VERSION ""

NS_ :

BS_:

BU_: XXX

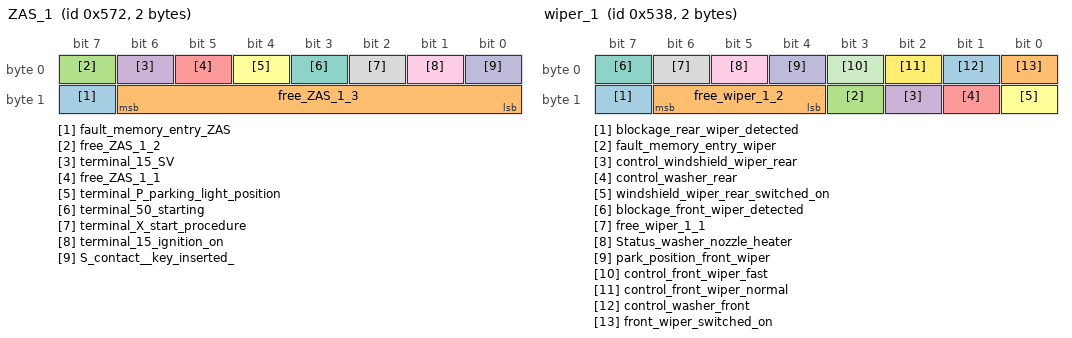
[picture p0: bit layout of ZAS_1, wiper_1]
BO_ 1394 ZAS_1: 2 XXX
 SG_ fault_memory_entry_ZAS : 15|1@1+ (1,0) [0|0] "" XXX
 SG_ free_ZAS_1_3 : 8|7@1+ (1,0) [0|0] "" XXX
 SG_ free_ZAS_1_2 : 7|1@1+ (1,0) [0|0] "" XXX
 SG_ terminal_15_SV : 6|1@1+ (1,0) [0|0] "" XXX
 SG_ free_ZAS_1_1 : 5|1@1+ (1,0) [0|0] "" XXX
 SG_ terminal_P_parking_light_position : 4|1@1+ (1,0) [0|0] "" XXX
 SG_ terminal_50_starting : 3|1@1+ (1,0) [0|0] "" XXX
 SG_ terminal_X_start_procedure : 2|1@1+ (1,0) [0|0] "" XXX
 SG_ terminal_15_ignition_on : 1|1@1+ (1,0) [0|0] "" XXX
 SG_ S_contact__key_inserted_ : 0|1@1+ (1,0) [0|0] "" XXX

BO_ 1336 wiper_1: 2 XXX
 SG_ blockage_rear_wiper_detected : 15|1@1+ (1,0) [0|0] "" XXX
 SG_ free_wiper_1_2 : 12|3@1+ (1,0) [0|0] "" XXX
 SG_ fault_memory_entry_wiper : 11|1@1+ (1,0) [0|0] "" XXX
 SG_ control_windshield_wiper_rear : 10|1@1+ (1,0) [0|0] "" XXX
 SG_ control_washer_rear : 9|1@1+ (1,0) [0|0] "" XXX
 SG_ windshield_wiper_rear_switched_on : 8|1@1+ (1,0) [0|0] "" XXX
 SG_ blockage_front_wiper_detected : 7|1@1+ (1,0) [0|0] "" XXX
 SG_ free_wiper_1_1 : 6|1@1+ (1,0) [0|0] "" XXX
 SG_ Status_washer_nozzle_heater : 5|1@1+ (1,0) [0|0] "" XXX
 SG_ park_position_front_wiper : 4|1@1+ (1,0) [0|0] "" XXX
 SG_ control_front_wiper_fast : 3|1@1+ (1,0) [0|0] "" XXX
 SG_ control_front_wiper_normal : 2|1@1+ (1,0) [0|0] "" XXX
 SG_ control_washer_front : 1|1@1+ (1,0) [0|0] "" XXX
 SG_ front_wiper_switched_on : 0|1@1+ (1,0) [0|0] "" XXX

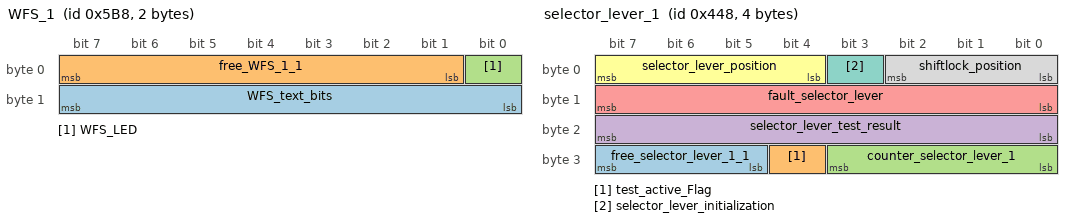
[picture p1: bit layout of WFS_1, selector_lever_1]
BO_ 1464 WFS_1: 2 XXX
 SG_ WFS_text_bits : 8|8@1+ (1,0) [0|0] "" XXX
 SG_ free_WFS_1_1 : 1|7@1+ (1,0) [0|0] "" XXX
 SG_ WFS_LED : 0|1@1+ (1,0) [0|0] "" XXX

BO_ 1096 selector_lever_1: 4 XXX
 SG_ free_selector_lever_1_1 : 29|3@1+ (1,0) [0|0] "" XXX
 SG_ test_active_Flag : 28|1@1+ (1,0) [0|0] "" XXX
 SG_ counter_selector_lever_1 : 24|4@1+ (1,0) [0|15] "" XXX
 SG_ selector_lever_test_result : 16|8@1+ (1,0) [0|255] "" XXX
 SG_ fault_selector_lever : 8|8@1+ (1,0) [0|0] "" XXX
 SG_ selector_lever_position : 4|4@1+ (1,0) [0|0] "" XXX
 SG_ selector_lever_initialization : 3|1@1+ (1,0) [0|0] "" XXX
 SG_ shiftlock_position : 0|3@1+ (1,0) [0|0] "" XXX

BO_ 1496 installation_list_1: 8 XXX
 SG_ TV_tuner : 63|1@1+ (1,0) [0|0] "" XXX
 SG_ DSP : 62|1@1+ (1,0) [0|0] "" XXX
 SG_ CD_changer : 61|1@1+ (1,0) [0|0] "" XXX
 SG_ voice_input : 60|1@1+ (1,0) [0|0] "" XXX
 SG_ telematics : 59|1@1+ (1,0) [0|0] "" XXX
 SG_ Navigation : 58|1@1+ (1,0) [0|0] "" XXX
 SG_ telephone : 57|1@1+ (1,0) [0|0] "" XXX
 SG_ Radio : 56|1@1+ (1,0) [0|0] "" XXX
 SG_ MMI_front : 55|1@1+ (1,0) [0|0] "" XXX
 SG_ MMI_rear : 54|1@1+ (1,0) [0|0] "" XXX
 SG_ free_installation_list_1_11 : 53|1@1+ (1,0) [0|0] "" XXX
 SG_ climate_control_panel_HL : 52|1@1+ (1,0) [0|0] "" XXX
 SG_ free_installation_list_1_10 : 50|2@1+ (1,0) [0|0] "" XXX
 SG_ fuel_level_sender : 49|1@1+ (1,0) [0|0] "" XXX
 SG_ assist_driving_light : 48|1@1+ (1,0) [0|0] "" XXX
 SG_ Memory_behind_driver : 47|1@1+ (1,0) [0|0] "" XXX
 SG_ seat_memory_rear : 46|1@1+ (1,0) [0|0] "" XXX
 SG_ seat_memory_passenger : 45|1@1+ (1,0) [0|0] "" XXX
 SG_ trailer_control_unit : 44|1@1+ (1,0) [0|0] "" XXX
 SG_ energy_management : 43|1@1+ (1,0) [0|0] "" XXX
 SG_ wiper_module : 42|1@1+ (1,0) [0|0] "" XXX
 SG_ EZS___Kessy__comfort_ : 41|1@1+ (1,0) [0|0] "" XXX
 SG_ convertible_top_control_unit : 40|1@1+ (1,0) [0|0] "" XXX
 SG_ auxiliary_heater : 39|1@1+ (1,0) [0|0] "" XXX
 SG_ free_installation_list_1_9 : 38|1@1+ (1,0) [0|0] "" XXX
 SG_ park_assist : 37|1@1+ (1,0) [0|0] "" XXX
 SG_ climate_control_unit_comfort : 36|1@1+ (1,0) [0|0] "" XXX
 SG_ Gateway : 35|1@1+ (1,0) [0|0] "" XXX
 SG_ steering_column_module : 34|1@1+ (1,0) [0|0] "" XXX
 SG_ tire_pressure : 33|1@1+ (1,0) [0|0] "" XXX
 SG_ instrument_cluster_comfort : 32|1@1+ (1,0) [0|0] "" XXX
 SG_ roof_module : 31|1@1+ (1,0) [0|0] "" XXX
 SG_ Memory : 30|1@1+ (1,0) [0|0] "" XXX
 SG_ TSG_HR : 29|1@1+ (1,0) [0|0] "" XXX
 SG_ TSG_HL : 28|1@1+ (1,0) [0|0] "" XXX
 SG_ TSG_BT : 27|1@1+ (1,0) [0|0] "" XXX
 SG_ TSG_FT : 26|1@1+ (1,0) [0|0] "" XXX
 SG_ ZKE : 25|1@1+ (1,0) [0|0] "" XXX
 SG_ BSG_comfort : 24|1@1+ (1,0) [0|0] "" XXX
 SG_ free_installation_list_1_8 : 19|5@1+ (1,0) [0|0] "" XXX
 SG_ Stabi_decoupling : 18|1@1+ (1,0) [0|0] "" XXX
 SG_ selector_lever : 17|1@1+ (1,0) [0|0] "" XXX
 SG_ battery_manager : 16|1@1+ (1,0) [0|0] "" XXX
 SG_ damper_SG : 15|1@1+ (1,0) [0|0] "" XXX
 SG_ level_control : 14|1@1+ (1,0) [0|0] "" XXX
 SG_ EZS___Kessy__drive_ : 13|1@1+ (1,0) [0|0] "" XXX
 SG_ brake_booster : 12|1@1+ (1,0) [0|0] "" XXX
 SG_ steering_assist : 11|1@1+ (1,0) [0|0] "" XXX
 SG_ instrument_cluster_drive : 10|1@1+ (1,0) [0|0] "" XXX
 SG_ injection_pump : 9|1@1+ (1,0) [0|0] "" XXX
 SG_ steering_angle : 8|1@1+ (1,0) [0|0] "" XXX
 SG_ all_wheel_drive : 7|1@1+ (1,0) [0|0] "" XXX
 SG_ BSG_drive : 6|1@1+ (1,0) [0|0] "" XXX
 SG_ ADR : 5|1@1+ (1,0) [0|0] "" XXX
 SG_ airbag : 4|1@1+ (1,0) [0|0] "" XXX
 SG_ Climatronic_drive : 3|1@1+ (1,0) [0|0] "" XXX
 SG_ ABS : 2|1@1+ (1,0) [0|0] "" XXX
 SG_ transmission_control_unit : 1|1@1+ (1,0) [0|0] "" XXX
 SG_ engine_control_unit : 0|1@1+ (1,0) [0|0] "" XXX

BO_ 1488 system_info_1: 6 XXX
 SG_ CAN_state_4_1_powertrain_data_main : 44|4@1+ (1,0) [0|15] "" XXX
 SG_ CAN_state_4_1_powertrain_data_secondary : 40|4@1+ (1,0) [0|15] "" XXX
 SG_ CAN_state_4_1_comfort_data_main : 36|4@1+ (1,0) [0|15] "" XXX
 SG_ CAN_state_4_1_comfort_data_secondary : 32|4@1+ (1,0) [0|15] "" XXX
 SG_ free_system_info_1_6 : 30|1@1+ (1,0) [0|0] "" XXX
 SG_ four_door : 29|1@1+ (1,0) [0|0] "" XXX
 SG_ right_hand_drive : 28|1@1+ (1,0) [0|0] "" XXX
 SG_ vehicle_index : 24|4@1+ (1,0) [0|0] "" XXX
 SG_ vehicle_generation : 20|4@1+ (1,0) [0|15] "" XXX
 SG_ vehicle_derivative : 16|4@1+ (1,0) [0|15] "" XXX
 SG_ vehicle_brand_2 : 12|4@1+ (1,0) [0|15] "" XXX
 SG_ vehicle_class : 8|4@1+ (1,0) [0|15] "" XXX
 SG_ installation_info_valid : 7|1@1+ (1,0) [0|0] "" XXX
 SG_ CAN_Infotainment_installed : 6|1@1+ (1,0) [0|0] "" XXX
 SG_ CAN_Infotainment_in_diagnosis : 5|1@1+ (1,0) [0|0] "" XXX
 SG_ Sleep_CAN_infotainment : 4|1@1+ (1,0) [0|0] "" XXX
 SG_ CAN_comfort_in_diagnosis : 3|1@1+ (1,0) [0|0] "" XXX
 SG_ Sleep_CAN_comfort : 2|1@1+ (1,0) [0|0] "" XXX
 SG_ CAN_powertrain_in_diagnosis : 1|1@1+ (1,0) [0|0] "" XXX
 SG_ CAN_external_connected : 0|1@1+ (1,0) [0|0] "" XXX

BO_ 268 Slave_1: 8 XXX
 SG_ Delta_reduced_desired_torque : 48|1@1+ (1,0) [0|0] "" XXX
 SG_ Delta_throttle_valve_angle : 32|16@1+ (1,0) [0|0] "" XXX
 SG_ free_Slave_1_1 : 25|7@1+ (1,0) [0|0] "" XXX
 SG_ Delta_ignition_angle_output : 24|1@1+ (1,0) [0|0] "" XXX
 SG_ Ubat_enable_DVE_Slave : 23|1@1+ (1,0) [0|0] "" XXX
 SG_ throttle_valve_setpoint_limitation : 22|1@1+ (1,0) [0|0] "" XXX
 SG_ injection_inhibit_learn_Slave : 21|1@1+ (1,0) [0|0] "" XXX
 SG_ Master_detected_Slave : 20|1@1+ (1,0) [0|0] "" XXX
 SG_ fault_torque_output : 19|1@1+ (1,0) [0|0] "" XXX
 SG_ fault_transmission_torque : 18|1@1+ (1,0) [0|0] "" XXX
 SG_ fault_brake_message : 17|1@1+ (1,0) [0|0] "" XXX
 SG_ indicated_actual_torque_Slave : 0|16@1+ (0.0015259,0) [0|99.998] "%" XXX
 SG_ Timeout_brake_message : 0|1@1+ (1,0) [0|0] "" XXX

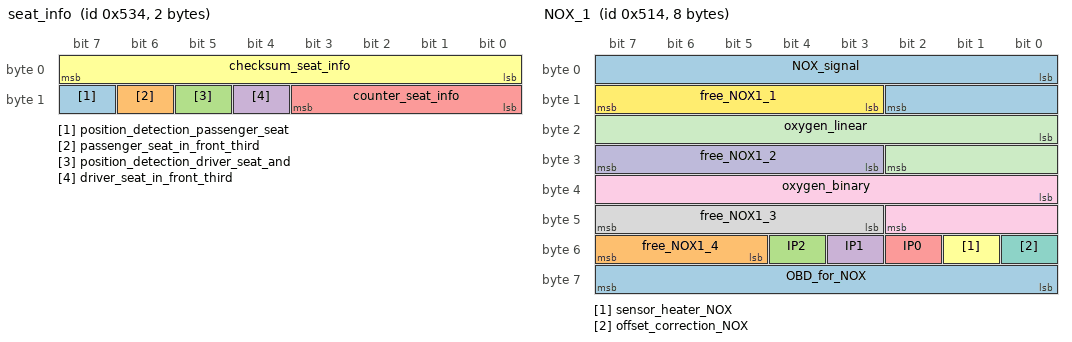
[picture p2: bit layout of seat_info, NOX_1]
BO_ 1332 seat_info: 2 XXX
 SG_ position_detection_passenger_seat : 15|1@1+ (1,0) [0|0] "" XXX
 SG_ passenger_seat_in_front_third : 14|1@1+ (1,0) [0|0] "" XXX
 SG_ position_detection_driver_seat_and : 13|1@1+ (1,0) [0|0] "" XXX
 SG_ driver_seat_in_front_third : 12|1@1+ (1,0) [0|0] "" XXX
 SG_ counter_seat_info : 8|4@1+ (1,0) [0|15] "" XXX
 SG_ checksum_seat_info : 0|8@1+ (1,0) [0|0] "" XXX

BO_ 1810 PSG_3: 2 XXX
 SG_ self_test_result : 0|16@1+ (1,0) [0|0] "" XXX

BO_ 1298 PSG_2: 8 XXX
 SG_ RAM_content_4 : 48|16@1+ (1,0) [0|0] "" XXX
 SG_ RAM_content_3 : 32|16@1+ (1,0) [0|0] "" XXX
 SG_ RAM_content_2 : 16|16@1+ (1,0) [0|0] "" XXX
 SG_ RAM_content_1 : 0|16@1+ (1,0) [0|0] "" XXX

BO_ 274 PSG_1: 8 XXX
 SG_ pump_temperature__2_1_ : 48|16@1+ (0.0625,0) [0|4096] "K" XXX
 SG_ pump_temperature__3_2_2_ : 44|12@1+ (1,0) [0|0] "" XXX
 SG_ cylinder_counter__3_2_2_ : 43|3@1+ (1,0) [1|8] "counter" XXX
 SG_ control_duration__3_2_2_ : 32|11@1+ (0.0469,0) [0|96] "NW" XXX
 SG_ camshaft_rpm__3_2_2_ : 20|12@1+ (4,0) [0|16380] "upm" XXX
 SG_ pump_status_word__3_2_2_ : 0|20@1+ (1,0) [0|0] "" XXX

BO_ 1300 NOX_1: 8 XXX
 SG_ OBD_for_NOX : 56|8@1+ (1,0) [0|0] "" XXX
 SG_ free_NOX1_4 : 53|3@1+ (1,0) [0|0] "" XXX
 SG_ IP2 : 52|1@1+ (1,0) [0|0] "" XXX
 SG_ IP1 : 51|1@1+ (1,0) [0|0] "" XXX
 SG_ IP0 : 50|1@1+ (1,0) [0|0] "" XXX
 SG_ sensor_heater_NOX : 49|1@1+ (1,0) [0|0] "" XXX
 SG_ offset_correction_NOX : 48|1@1+ (1,0) [0|0] "" XXX
 SG_ free_NOX1_3 : 43|5@1+ (1,0) [0|0] "" XXX
 SG_ oxygen_binary : 32|11@1+ (1,-200) [-200|1847] "mV" XXX
 SG_ free_NOX1_2 : 27|5@1+ (1,0) [0|0] "" XXX
 SG_ oxygen_linear : 16|11@1+ (1,0) [0|2047] "1000/Lambd" XXX
 SG_ free_NOX1_1 : 11|5@1+ (1,0) [0|0] "" XXX
 SG_ NOX_signal : 0|11@1+ (1,0) [0|2047] "ppm" XXX

BO_ 1424 level_1: 6 XXX
 SG_ load_state : 40|8@1+ (1,0) [0|253] "Zuladung" XXX
 SG_ fault_memory_entry_level_1 : 39|1@1+ (1,0) [0|0] "" XXX
 SG_ system_status_level_1 : 38|1@1+ (1,0) [0|0] "" XXX
 SG_ reserve_vehicle_type : 37|1@1+ (1,0) [0|0] "" XXX
 SG_ vehicle_type_level : 36|1@1+ (1,0) [0|0] "" XXX
 SG_ text_bits_level_1 : 32|4@1+ (1,0) [0|0] "" XXX
 SG_ adjustment_HL : 31|1@1+ (1,0) [0|0] "" XXX
 SG_ adjustment_HR : 30|1@1+ (1,0) [0|0] "" XXX
 SG_ adjustment_VL : 29|1@1+ (1,0) [0|0] "" XXX
 SG_ adjustment_VR : 28|1@1+ (1,0) [0|0] "" XXX
 SG_ lowering_vehicle : 27|1@1+ (1,0) [0|0] "" XXX
 SG_ raise_vehicle : 26|1@1+ (1,0) [0|0] "" XXX
 SG_ adjustment_active : 25|1@1+ (1,0) [0|0] "" XXX
 SG_ compressor_run_shortly : 24|1@1+ (1,0) [0|0] "" XXX
 SG_ free_level_1_5 : 23|1@1+ (1,0) [0|0] "" XXX
 SG_ button_level : 22|1@1+ (1,0) [0|0] "" XXX
 SG_ park_level : 21|1@1+ (1,0) [0|0] "" XXX
 SG_ intermediate_level : 20|1@1+ (1,0) [0|0] "" XXX
 SG_ level_status : 16|4@1+ (1,0) [0|0] "" XXX
 SG_ MSG_limitation : 15|1@1+ (1,0) [0|0] "" XXX
 SG_ ESP_influence : 14|1@1+ (1,0) [0|0] "" XXX
 SG_ warning_lamp_level_1 : 13|1@1+ (1,0) [0|0] "" XXX
 SG_ free_level_1_1 : 12|1@1+ (1,0) [0|0] "" XXX
 SG_ counter_level_1 : 8|4@1+ (1,0) [0|15] "counter" XXX
 SG_ checksum_level_1 : 0|8@1+ (1,0) [0|0] "" XXX

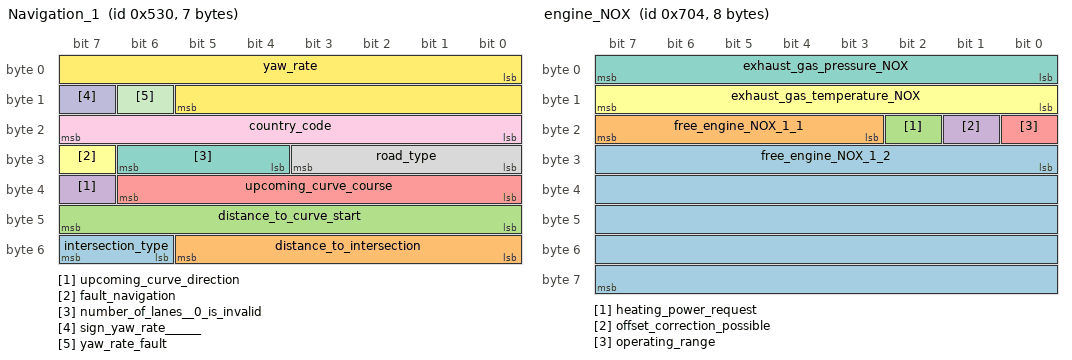
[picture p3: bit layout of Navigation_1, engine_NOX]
BO_ 1328 Navigation_1: 7 XXX
 SG_ intersection_type : 54|2@1+ (1,0) [0|3] "" XXX
 SG_ distance_to_intersection : 48|6@1+ (5,0) [0|315] "m" XXX
 SG_ distance_to_curve_start : 40|8@1+ (1,0) [0|255] "m" XXX
 SG_ upcoming_curve_direction : 39|1@1+ (1,0) [0|0] "" XXX
 SG_ upcoming_curve_course : 32|7@1+ (50,0) [0|6350] "m" XXX
 SG_ fault_navigation : 31|1@1+ (1,0) [0|0] "" XXX
 SG_ number_of_lanes__0_is_invalid : 28|3@1+ (1,0) [1|7] "" XXX
 SG_ road_type : 24|4@1+ (1,0) [0|15] "" XXX
 SG_ country_code : 16|8@1+ (1,0) [0|0] "" XXX
 SG_ sign_yaw_rate______ : 15|1@1+ (1,0) [0|0] "" XXX
 SG_ yaw_rate_fault : 14|1@1+ (1,0) [0|0] "" XXX
 SG_ yaw_rate : 0|14@1+ (0.01,0) [0|100] "deg/sek" XXX

BO_ 1792 MSG_3: 3 XXX
 SG_ MSG_configuration : 16|8@1+ (1,0) [0|0] "" XXX
 SG_ position_of_OT_pulse : 0|16@1+ (0.01172,-384) [-384|384] "KW" XXX

BO_ 1280 MSG_2: 8 XXX
 SG_ RAM_address_4 : 48|16@1+ (1,0) [0|0] "" XXX
 SG_ RAM_address_3 : 32|16@1+ (1,0) [0|0] "" XXX
 SG_ RAM_address_2 : 16|16@1+ (1,0) [0|0] "" XXX
 SG_ RAM_address_1 : 0|16@1+ (1,0) [0|0] "" XXX

BO_ 256 MSG_1: 8 XXX
 SG_ crankshaft_rpm_3_2_2 : 56|8@1+ (1,0) [0|0] "" XXX
 SG_ desired_delivery_start_KW__3_2_2_ : 40|16@1+ (0.01172,-384) [-384|384] "KW" XXX
 SG_ desired_delivery_start_NW__3_2_2_ : 28|12@1+ (0.01172,0) [0|768] "degNW" XXX
 SG_ desired_pre_injection : 16|12@1+ (1,0) [0|0] "" XXX
 SG_ desired_injection_quantity : 0|16@1+ (0.03125,0) [0|2047] "mg/H" XXX

BO_ 1796 engine_NOX: 8 XXX
 SG_ free_engine_NOX_1_2 : 24|40@1+ (1,0) [0|0] "" XXX
 SG_ free_engine_NOX_1_1 : 19|5@1+ (1,0) [0|0] "" XXX
 SG_ heating_power_request : 18|1@1+ (1,0) [0|0] "" XXX
 SG_ offset_correction_possible : 17|1@1+ (1,0) [0|0] "" XXX
 SG_ operating_range : 16|1@1+ (1,0) [0|0] "" XXX
 SG_ exhaust_gas_temperature_NOX : 8|8@1+ (5,-40) [-40|1230] "C" XXX
 SG_ exhaust_gas_pressure_NOX : 0|8@1+ (5,600) [600|1870] "mbar" XXX

BO_ 900 engine_torques: 8 XXX
 SG_ torque_values_inaccurate_torque : 35|2@1+ (1,0) [0|0] "" XXX

BO_ 1408 engine_Flexia: 8 XXX
 SG_ intake_system m0 : 63|1@1+ (1,0) [0|0] "" XXX
 SG_ displacement m0 : 56|7@1+ (0.1,0) [0|12.7] "l" XXX
 SG_ slope_of_the_filling_characteristic_curve m1 : 56|8@1+ (0.001,0) [0|0.255] "l/mm" XXX
 SG_ number_of_cylinders m0 : 52|4@1+ (1,0) [0|15] "Vent./Zyl." XXX
 SG_ rating_factor_soot_index_Turb m1 : 50|6@1+ (0.1,0) [0|6.3] "" XXX
 SG_ number_of_valves m0 : 49|3@1+ (1,0) [0|7] "Vent./Zyl." XXX
 SG_ rating_factor_wear_index m1 : 44|6@1+ (0.1,0) [0|6.3] "" XXX
 SG_ manufacturer_Code m1 : 40|4@1+ (1,0) [0|15] "" XXX
 SG_ engine_power m0 : 40|9@1+ (1,0) [0|512] "KW" XXX
 SG_ Max_torque m0 : 32|8@1+ (10,0) [0|2550] "Nm" XXX
 SG_ normalized_consumption m1 : 32|8@1+ (10,0) [0|2550] "l/Zyl." XXX
 SG_ oil_level_threshold m1 : 24|8@1+ (0.25,0) [0|63.75] "cm" XXX
 SG_ rpm_MaxNorm m0 : 24|8@1+ (100,0) [0|25500] "U/min" XXX
 SG_ wear_index : 16|8@1+ (1,0) [0|254] "" XXX
 SG_ soot_index : 8|8@1+ (1,0) [0|254] "" XXX
 SG_ combustion_type : 7|1@1+ (1,0) [0|0] "" XXX
 SG_ free_engine_Flexia_1 : 6|1@1+ (1,0) [0|0] "" XXX
 SG_ Warm_Up_Cycle : 5|1@1+ (1,0) [0|0] "" XXX
 SG_ Driving_Cycle : 4|1@1+ (1,0) [0|0] "" XXX
 SG_ counter_engine_Flexia : 1|3@1+ (1,0) [0|15] "" XXX
 SG_ multiplex_switch_engine_Flexia M : 0|1@1+ (1,0) [0|0] "" XXX

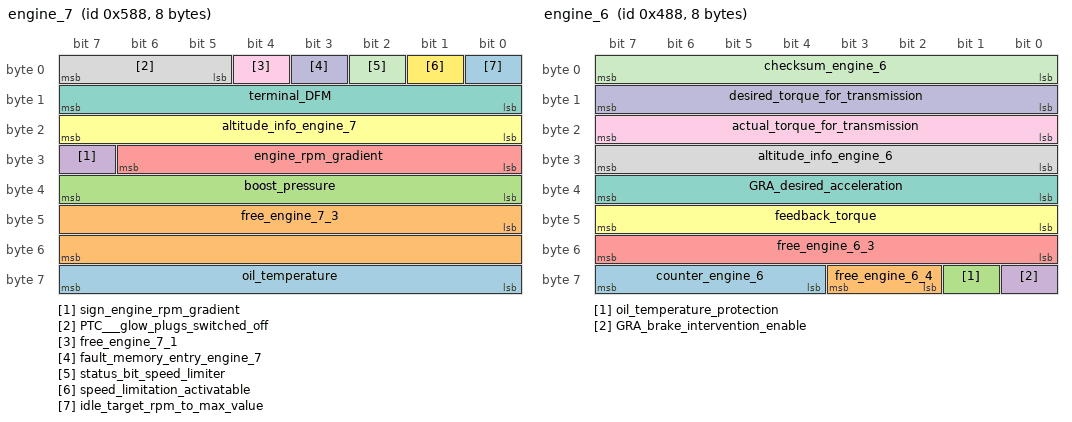
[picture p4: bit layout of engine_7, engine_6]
BO_ 1416 engine_7: 8 XXX
 SG_ oil_temperature : 56|8@1+ (1,0) [0|0] "" XXX
 SG_ free_engine_7_3 : 40|16@1+ (1,0) [0|0] "" XXX
 SG_ boost_pressure : 32|8@1+ (0.01,0) [0|2.54] "bar" XXX
 SG_ sign_engine_rpm_gradient : 31|1@1+ (1,0) [0|0] "" XXX
 SG_ engine_rpm_gradient : 24|7@1+ (1,0) [0|126] "U/min" XXX
 SG_ altitude_info_engine_7 : 16|8@1+ (0.00787,0) [0|2] "" XXX
 SG_ terminal_DFM : 8|8@1+ (0.4,0) [0|101.6] "%" XXX
 SG_ PTC___glow_plugs_switched_off : 5|3@1+ (1,0) [0|0] "" XXX
 SG_ free_engine_7_1 : 4|1@1+ (1,0) [0|0] "" XXX
 SG_ fault_memory_entry_engine_7 : 3|1@1+ (1,0) [0|0] "" XXX
 SG_ status_bit_speed_limiter : 2|1@1+ (1,0) [0|0] "" XXX
 SG_ speed_limitation_activatable : 1|1@1+ (1,0) [0|0] "" XXX
 SG_ idle_target_rpm_to_max_value : 0|1@1+ (1,0) [0|0] "" XXX

BO_ 1160 engine_6: 8 XXX
 SG_ counter_engine_6 : 60|4@1+ (1,0) [0|15] "" XXX
 SG_ free_engine_6_4 : 58|2@1+ (1,0) [0|0] "" XXX
 SG_ oil_temperature_protection : 57|1@1+ (1,0) [0|0] "" XXX
 SG_ GRA_brake_intervention_enable : 56|1@1+ (1,0) [0|0] "" XXX
 SG_ free_engine_6_3 : 48|8@1+ (1,0) [0|0] "" XXX
 SG_ feedback_torque : 40|8@1+ (0.39,0) [0|100] "" XXX
 SG_ GRA_desired_acceleration : 32|8@1+ (0.024,-3.984) [-3.984|2.112] "m/s2" XXX
 SG_ altitude_info_engine_6 : 24|8@1+ (0.00787,0) [0|2] "" XXX
 SG_ actual_torque_for_transmission : 16|8@1+ (0.39,0) [0|99] "MDI" XXX
 SG_ desired_torque_for_transmission : 8|8@1+ (0.39,0) [0|99] "MDI" XXX
 SG_ checksum_engine_6 : 0|8@1+ (1,0) [0|0] "" XXX

BO_ 1152 engine_5: 8 engine
 SG_ MO5_Mp_Code M : 6|2@1+ (1,0) [0|3] "" Gateway
 SG_ MO5_max_torque m0 : 0|6@1+ (10,0) [0|630] "Nm" Gateway
 SG_ MO5_engine_speed m1 : 0|6@1+ (100,0) [0|6300] "U/min" Gateway
 SG_ MO5_engine_type m2 : 0|6@1+ (1,0) [0|63] "" Gateway
 SG_ MO5_exhaust_type m3 : 0|1@1+ (1,0) [0|1] "" Gateway
 SG_ MO5_exhaust_type2 m3 : 1|1@1+ (1,0) [0|1] "" Gateway
 SG_ MO5_exhaust_type3 m3 : 2|1@1+ (1,0) [0|1] "" Gateway
 SG_ OBD_cold_start_Denominator m3 : 3|1@1+ (1,0) [0|1] "" Gateway
 SG_ OBD_Minimum_Trip m3 : 4|1@1+ (1,0) [0|1] "" Gateway
 SG_ MO5_DPF_reg m3 : 5|1@1+ (1,0) [0|1] "" Gateway
 SG_ MO5_preheat : 9|1@1+ (1,0) [0|1] "" KOMBI
 SG_ MO5_E_throttle : 10|1@1+ (1,0) [0|1] "" KOMBI
 SG_ MO5_OBD_2 : 11|1@1+ (1,0) [0|1] "" KOMBI
 SG_ MO5_hot_run : 12|1@1+ (1,0) [0|1] "" KOMBI
 SG_ MO5_climate_compressor : 13|1@1+ (1,0) [0|1] "" Gateway
 SG_ MO5_field_cooling : 14|1@1+ (1,0) [0|1] "" Gateway
 SG_ MO5_KliKo_Red : 15|1@1+ (1,0) [0|1] "" Gateway
 SG_ MO5_consumption : 16|15@1+ (1,0) [0|32767] "µl" KOMBI
 SG_ MO5_overflow_consumption : 31|1@1+ (1,0) [0|1] "" KOMBI
 SG_ MO5_fan : 32|8@1+ (0.4,0) [0|101.6] "%" Gateway
 SG_ MO5_HLeuchte : 40|1@1+ (1,0) [0|1] "" KOMBI
 SG_ MO5_particle_lamp : 41|1@1+ (1,0) [0|1] "" KOMBI
 SG_ MO5_Sta_BKU : 42|1@1+ (1,0) [0|1] "" Gateway
 SG_ MO5_type_start_control : 43|1@1+ (1,0) [0|1] "" Gateway
 SG_ MO5_TDE_lamp : 44|1@1+ (1,0) [0|1] "" KOMBI
 SG_ MO5_TDE_Text : 45|1@1+ (1,0) [0|1] "" KOMBI
 SG_ MO5_DZM_damping : 46|1@1+ (1,0) [0|1] "" KOMBI
 SG_ MO5_Interlock : 47|1@1+ (1,0) [0|1] "" Gateway
 SG_ MO5_Start : 48|1@1+ (1,0) [0|1] "" Gateway
 SG_ MO5_starter : 49|1@1+ (1,0) [0|1] "" Gateway
 SG_ MO5_GRA_main_switch : 50|1@1+ (1,0) [0|1] "" Gateway
 SG_ MO5_torques : 51|1@1+ (1,0) [0|1] "" Gateway
 SG_ MO5_engine_text1 : 52|1@1+ (1,0) [0|1] "" KOMBI
 SG_ MO5_engine_text2 : 53|1@1+ (1,0) [0|1] "" KOMBI
 SG_ MO5_engine_text3 : 54|1@1+ (1,0) [0|1] "" KOMBI
 SG_ MO5_engine_text4 : 55|1@1+ (1,0) [0|1] "" KOMBI
 SG_ CHECKSUM : 56|8@1+ (1,0) [0|255] "" Gateway

BO_ 896 engine_3: 8 engine
 SG_ MO3_preglow : 0|1@1+ (1,0) [0|1] "" Gateway
 SG_ MO3_Prio_Dz : 1|1@1+ (1,0) [0|1] "" Transmission
 SG_ MO_switch_StartStopp : 2|1@1+ (1,0) [0|1] "" Gateway
 SG_ MO3_winter_program : 3|1@1+ (1,0) [0|1] "" Transmission
 SG_ MO3_Sta_pedal : 4|1@1+ (1,0) [0|1] "" Gateway
 SG_ MO3_Sta_FPG M : 5|1@1+ (1,0) [0|1] "" ESP
 SG_ MO3_Sign_FPG m1 : 6|1@1+ (1,0) [0|1] "" ESP
 SG_ MO3_Sta_temp : 7|1@1+ (1,0) [0|1] "" Gateway
 SG_ MO3_offset_temp : 8|8@1+ (0.75,-48) [-48|142.5] "°C" Gateway
 SG_ MO3_pedal_value : 16|8@1+ (0.4,0) [0|101.6] "%" Gateway
 SG_ MO3_wheel_Wu_torque : 24|12@1+ (0.39,0) [0|1596.66] "%" Transmission
 SG_ MO3_sign_wheelWu : 36|1@1+ (1,0) [0|1] "" Transmission
 SG_ MO3_release_coasting : 37|1@1+ (1,0) [0|1] "" Transmission
 SG_ MO_StartStopp_stop_preparation : 38|1@1+ (1,0) [0|1] "" Gateway
 SG_ MO3_Dz_influence : 40|8@1+ (0.39,0) [0|99.45] "%" Transmission
 SG_ MO3_target_Dz : 48|8@1+ (25,0) [0|6350] "U/min" Transmission
 SG_ MO3_DKW m0 : 56|8@1+ (0.4,0) [0|101.6] "%" Gateway
 SG_ MO3_FPGradient m1 : 56|8@1+ (25,0) [0|6350] "%/s" ESP

BO_ 648 engine_2: 8 engine
 SG_ MO2_Mp_code m : 6|2@1+ (1,0) [0|3] "" Gateway
 SG_ MO2_transmission_code m2 : 0|6@1+ (1,0) [0|63] "" Gateway
 SG_ MO2_max_torque m3 : 0|6@1+ (10,0) [0|630] "Nm" Gateway
 SG_ MO2_CAN_version m0 : 0|6@1+ (1,0) [0|63] "" Gateway
 SG_ MO2_motor_code m1 : 0|6@1+ (1,0) [0|63] "" Gateway
 SG_ MO2_coolant_T : 8|8@1+ (0.75,-48) [-47.25|142.5] "°C" Gateway
 SG_ MO2_BLS : 16|1@1+ (1,0) [0|1] "" Gateway
 SG_ MO2_BTS : 17|1@1+ (1,0) [0|1] "" Gateway
 SG_ MO2_Sta_coolant : 18|1@1+ (1,0) [0|1] "" Gateway
 SG_ MO2_Sta_climate : 19|1@1+ (1,0) [0|1] "" Gateway
 SG_ MO2_Sta_No_operation : 20|1@1+ (1,0) [0|1] "" Gateway
 SG_ MO2_Status_TSK : 21|1@1+ (1,0) [0|1] "" Gateway
 SG_ MO2_Sta_GRA : 22|2@1+ (1,0) [0|3] "" ACC,GRA
 SG_ TSK_limiter_selected : 25|1@1+ (1,0) [0|1] "" ACC,GRA
 SG_ MO2_GRA_controls : 26|1@1+ (1,0) [0|1] "" Gateway
 SG_ MO2_Sport_Error : 27|1@1+ (1,0) [0|1] "" Gateway
 SG_ MO2_OffRoad : 28|1@1+ (1,0) [0|1] "" Gateway
 SG_ MO2_RME_content : 29|3@1+ (12.5,0) [0|75] "%" Gateway
 SG_ MO2_GRA_target : 32|8@1+ (1.28,0) [0|325.12] "km/h" ACC,GRA
 SG_ MO2_LL_target_speed : 40|8@1+ (10,0) [0|2540] "1/min" Gateway
 SG_ MO2_limit_Mo : 48|8@1+ (0.39,0) [0|99.06] "%" Gateway
 SG_ MO2_Mo_ZWR : 56|8@1+ (0.39,0) [0|99.06] "%" Gateway

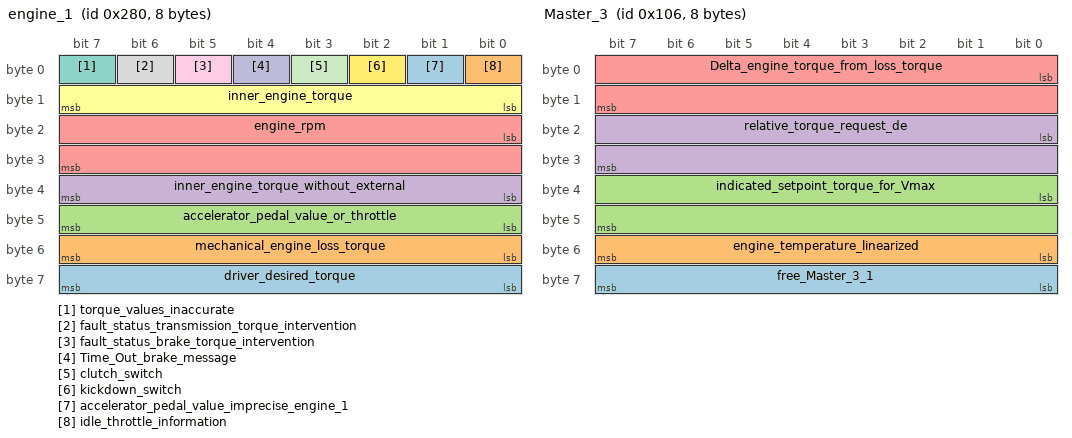
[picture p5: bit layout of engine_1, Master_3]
BO_ 640 engine_1: 8 XXX
 SG_ driver_desired_torque : 56|8@1+ (0.39,0) [0|99] "MDI" XXX
 SG_ mechanical_engine_loss_torque : 48|8@1+ (0.39,0) [0|99] "MDI" XXX
 SG_ accelerator_pedal_value_or_throttle : 40|8@1+ (0.4,0) [0|101.6] "%" XXX
 SG_ inner_engine_torque_without_external : 32|8@1+ (0.39,0) [0|99] "MDI" XXX
 SG_ engine_rpm : 16|16@1+ (0.25,0) [0|16256] "U/min" XXX
 SG_ inner_engine_torque : 8|8@1+ (0.39,0) [0|99] "MDI" XXX
 SG_ torque_values_inaccurate : 7|1@1+ (1,0) [0|0] "" XXX
 SG_ fault_status_transmission_torque_intervention : 6|1@1+ (1,0) [0|0] "" XXX
 SG_ fault_status_brake_torque_intervention : 5|1@1+ (1,0) [0|0] "" XXX
 SG_ Time_Out_brake_message : 4|1@1+ (1,0) [0|0] "" XXX
 SG_ clutch_switch : 3|1@1+ (1,0) [0|0] "" XXX
 SG_ kickdown_switch : 2|1@1+ (1,0) [0|0] "" XXX
 SG_ accelerator_pedal_value_imprecise_engine_1 M : 1|1@1+ (1,0) [0|0] "" XXX
 SG_ idle_throttle_information : 0|1@1+ (1,0) [0|0] "" XXX

BO_ 262 Master_3: 8 XXX
 SG_ free_Master_3_1 : 56|8@1+ (1,0) [0|0] "" XXX
 SG_ engine_temperature_linearized : 48|8@1+ (0.75,-48) [-48|143.25] "" XXX
 SG_ indicated_setpoint_torque_for_Vmax : 32|16@1+ (0.0015259,0) [0|100] "%" XXX
 SG_ relative_torque_request_de : 16|16@1+ (0.003052,0) [0|200] "%" XXX
 SG_ Delta_engine_torque_from_loss_torque : 0|16@1+ (0.003052,-100) [-100|100] "%" XXX

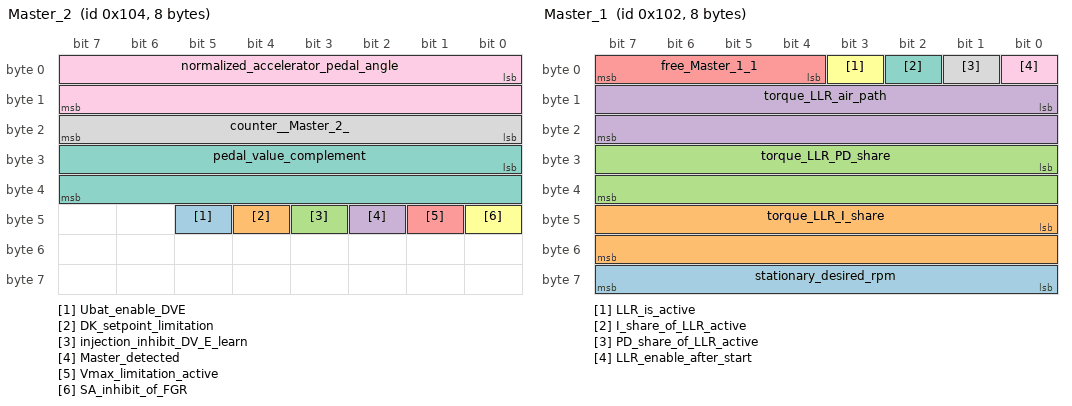
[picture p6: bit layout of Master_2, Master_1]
BO_ 260 Master_2: 8 XXX
 SG_ Ubat_enable_DVE : 45|1@1+ (1,0) [0|0] "" XXX
 SG_ DK_setpoint_limitation : 44|1@1+ (1,0) [0|0] "" XXX
 SG_ injection_inhibit_DV_E_learn : 43|1@1+ (1,0) [0|0] "" XXX
 SG_ Master_detected : 42|1@1+ (1,0) [0|0] "" XXX
 SG_ Vmax_limitation_active : 41|1@1+ (1,0) [0|0] "" XXX
 SG_ SA_inhibit_of_FGR : 40|1@1+ (1,0) [0|0] "" XXX
 SG_ pedal_value_complement : 24|16@1+ (1,0) [0|0] "" XXX
 SG_ counter__Master_2_ : 16|8@1+ (1,0) [0|255] "" XXX
 SG_ normalized_accelerator_pedal_angle : 0|16@1+ (0.001526,0) [0|100] "%" XXX

BO_ 258 Master_1: 8 XXX
 SG_ stationary_desired_rpm : 56|8@1+ (10,0) [0|2550] "Umin" XXX
 SG_ torque_LLR_I_share : 40|16@1+ (0.003052,-100) [-100|100] "%" XXX
 SG_ torque_LLR_PD_share : 24|16@1+ (0.003052,-100) [-100|100] "%" XXX
 SG_ torque_LLR_air_path : 8|16@1+ (0.003052,-100) [-100|100] "%" XXX
 SG_ free_Master_1_1 : 4|4@1+ (1,0) [0|0] "" XXX
 SG_ LLR_is_active : 3|1@1+ (1,0) [0|0] "" XXX
 SG_ I_share_of_LLR_active : 2|1@1+ (1,0) [0|0] "" XXX
 SG_ PD_share_of_LLR_active : 1|1@1+ (1,0) [0|0] "" XXX
 SG_ LLR_enable_after_start : 0|1@1+ (1,0) [0|0] "" XXX

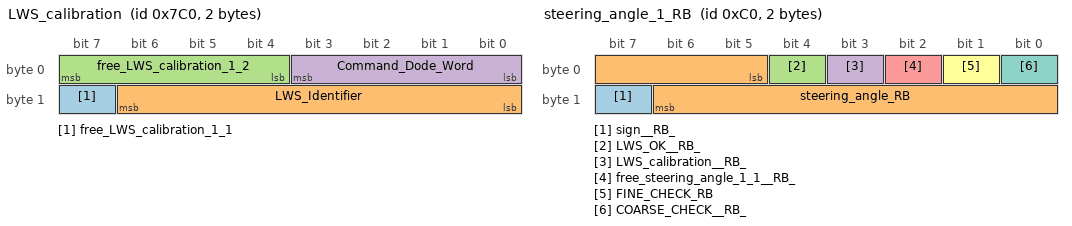
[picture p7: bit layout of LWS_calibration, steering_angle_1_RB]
BO_ 1984 LWS_calibration: 2 XXX
 SG_ free_LWS_calibration_1_1 : 15|1@1+ (1,0) [0|0] "" XXX
 SG_ LWS_Identifier : 8|7@1+ (1,0) [0|0] "" XXX
 SG_ free_LWS_calibration_1_2 : 4|4@1+ (1,0) [0|0] "" XXX
 SG_ Command_Dode_Word : 0|4@1+ (1,0) [0|0] "" XXX

BO_ 1986 steering_angle_Init: 4 XXX
 SG_ coding_bytes : 8|24@1+ (1,0) [0|0] "" XXX
 SG_ identifier_for_LWS_init : 0|8@1+ (1,0) [0|0] "" XXX

BO_ 192 steering_angle_1_RB: 2 XXX
 SG_ sign__RB_ : 15|1@1+ (1,0) [0|0] "" XXX
 SG_ steering_angle_RB : 5|10@1+ (2.5,-720) [-720|720] "" XXX
 SG_ LWS_OK__RB_ : 4|1@1+ (1,0) [0|0] "" XXX
 SG_ LWS_calibration__RB_ : 3|1@1+ (1,0) [0|0] "" XXX
 SG_ free_steering_angle_1_1__RB_ : 2|1@1+ (1,0) [0|0] "" XXX
 SG_ FINE_CHECK_RB : 1|1@1+ (1,0) [0|0] "" XXX
 SG_ COARSE_CHECK__RB_ : 0|1@1+ (1,0) [0|0] "" XXX

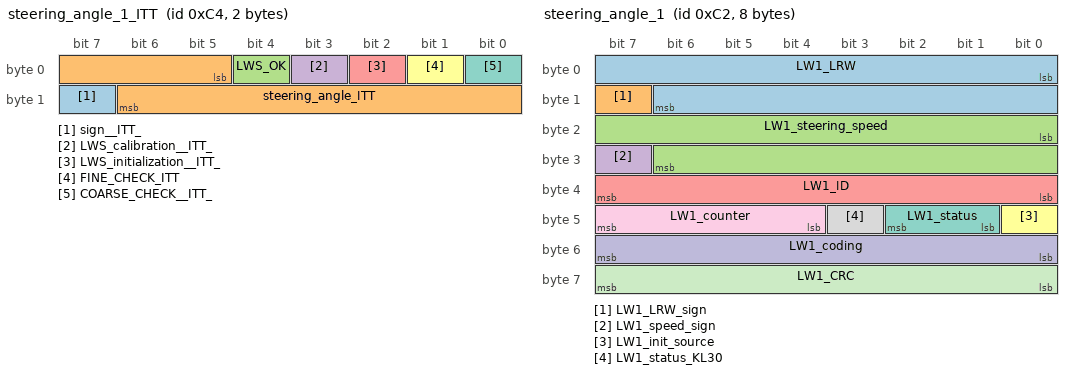
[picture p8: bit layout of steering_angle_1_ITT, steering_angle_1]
BO_ 196 steering_angle_1_ITT: 2 XXX
 SG_ sign__ITT_ : 15|1@1+ (1,0) [0|0] "" XXX
 SG_ steering_angle_ITT : 5|10@1+ (1.5,-768) [-768|766.5] "" XXX
 SG_ LWS_OK : 4|1@1+ (1,0) [0|0] "" XXX
 SG_ LWS_calibration__ITT_ : 3|1@1+ (1,0) [0|0] "" XXX
 SG_ LWS_initialization__ITT_ : 2|1@1+ (1,0) [0|0] "" XXX
 SG_ FINE_CHECK_ITT : 1|1@1+ (1,0) [0|0] "" XXX
 SG_ COARSE_CHECK__ITT_ : 0|1@1+ (1,0) [0|0] "" XXX

BO_ 194 steering_angle_1: 8 XXX
 SG_ LW1_LRW : 0|15@1+ (0.04375,0) [0|1433.55625] "°Grad" Gateway,ESP,ABS
 SG_ LW1_LRW_sign : 15|1@1+ (1,0) [0|1] "" Gateway,ESP,ABS
 SG_ LW1_steering_speed : 16|15@1+ (0.04375,0) [0|1433.55625] "°Grad/s" Gateway,ESP,ABS
 SG_ LW1_speed_sign : 31|1@1+ (1,0) [0|1] "" Gateway,ESP,ABS
 SG_ LW1_ID : 32|8@1+ (1,0) [0|255] "" Gateway,ESP,ABS
 SG_ LW1_init_source : 40|1@1+ (1,0) [0|1] "" Gateway,ESP,ABS
 SG_ LW1_status : 41|2@1+ (1,0) [0|3] "" Gateway,ESP,ABS
 SG_ LW1_status_KL30 : 43|1@1+ (1,0) [0|1] "" Gateway,ESP,ABS
 SG_ LW1_counter : 44|4@1+ (1,0) [0|15] "" Gateway,ESP,ABS
 SG_ LW1_coding : 48|8@1+ (1,0) [0|255] "" Gateway
 SG_ LW1_CRC : 56|8@1+ (1,0) [0|255] "" Gateway,ESP,ABS

BO_ 1502 steering_assist_fault: 7 XXX
 SG_ workshop_code : 48|8@1+ (1,0) [0|0] "" XXX
 SG_ multiplex_signal : 45|3@1+ (1,0) [0|7] "" XXX
 SG_ sensor_coding_steering_assist : 44|1@1+ (1,0) [0|0] "" XXX
 SG_ characteristic_curve_coding_steering_assist : 40|4@1+ (1,0) [0|15] "Kennlinie" XXX
 SG_ sensor_for_steering_angle_memory_read : 39|1@1+ (1,0) [0|0] "" XXX
 SG_ instrument_cluster_read_memory : 38|1@1+ (1,0) [0|0] "" XXX
 SG_ control_unit_read_out_memory : 37|1@1+ (1,0) [0|0] "" XXX
 SG_ steering_assist_ECU_defective : 36|1@1+ (1,0) [0|0] "" XXX
 SG_ free_power_steering_1_3 : 32|4@1+ (1,0) [0|0] "" XXX
 SG_ free_power_steering_1_4 : 30|2@1+ (1,0) [0|0] "" XXX
 SG_ sensor_for_steering_angle_no_CAN_comm : 29|1@1+ (1,0) [0|0] "" XXX
 SG_ sensor_for_steering_angle_no_CAN_comm : 28|1@1+ (1,0) [0|0] "" XXX
 SG_ instrument_cluster_no_CAN_communication_stored : 27|1@1+ (1,0) [0|0] "" XXX
 SG_ instrument_cluster_no_CAN_communication : 26|1@1+ (1,0) [0|0] "" XXX
 SG_ control_unit_no_CAN_communication_S : 25|1@1+ (1,0) [0|0] "" XXX
 SG_ control_unit_no_CAN_communication : 24|1@1+ (1,0) [0|0] "" XXX
 SG_ steering_assist_voltage_Ks_to_ground : 23|1@1+ (1,0) [0|0] "" XXX
 SG_ steering_assist_voltage_Ks_to_ground : 22|1@1+ (1,0) [0|0] "" XXX
 SG_ steering_assist_voltage_Ks_to_ground_stored : 21|1@1+ (1,0) [0|0] "" XXX
 SG_ steering_assist_voltage_Ks_to_ground : 20|1@1+ (1,0) [0|0] "" XXX
 SG_ steering_assist_temperature_protection_stored : 19|1@1+ (1,0) [0|0] "" XXX
 SG_ steering_assist_temperature_protection : 18|1@1+ (1,0) [0|0] "" XXX
 SG_ steering_assist_operation_implausible_signal_stored : 17|1@1+ (1,0) [0|0] "" XXX
 SG_ steering_assist_operation_implausible_signal : 16|1@1+ (1,0) [0|0] "" XXX
 SG_ steering_assist_sensor_no_communication_stored : 15|1@1+ (1,0) [0|0] "" XXX
 SG_ steering_assist_sensor_no_communication : 14|1@1+ (1,0) [0|0] "" XXX
 SG_ steering_assist_sensor_defective_stored : 13|1@1+ (1,0) [0|0] "" XXX
 SG_ steering_assist_sensor_defective : 12|1@1+ (1,0) [0|0] "" XXX
 SG_ steering_assist_sensor_interruption_stored : 11|1@1+ (1,0) [0|0] "" XXX
 SG_ steering_assist_sensor_interruption : 10|1@1+ (1,0) [0|0] "" XXX
 SG_ steering_assist_sensor_Ks_to_ground_stored : 9|1@1+ (1,0) [0|0] "" XXX
 SG_ steering_assist_sensor_Ks_to_ground : 8|1@1+ (1,0) [0|0] "" XXX
 SG_ voltage_terminal_15_too_low_sp_ : 7|1@1+ (1,0) [0|0] "" XXX
 SG_ voltage_terminal_15_too_low : 6|1@1+ (1,0) [0|0] "" XXX
 SG_ free_power_steering_1_5 : 4|2@1+ (1,0) [0|0] "" XXX
 SG_ voltage_terminal_30_too_low_sp_ : 3|1@1+ (1,0) [0|0] "" XXX
 SG_ voltage_terminal_30_too_low : 2|1@1+ (1,0) [0|0] "" XXX
 SG_ voltage_terminal_30_too_high_sp_ : 1|1@1+ (1,0) [0|0] "" XXX
 SG_ voltage_terminal_30_too_high : 0|1@1+ (1,0) [0|0] "" XXX

BO_ 976 steering_assist_1: 2 XXX
 SG_ LH1_load_info : 0|7@1+ (1,0) [0|127] "A" XXX
 SG_ LH1_error_LI : 7|1@1+ (1,0) [0|1] "" XXX
 SG_ LH1_safety_lamp : 8|1@1+ (1,0) [0|1] "" XXX
 SG_ LH1_error_lamp : 9|1@1+ (1,0) [0|1] "" XXX
 SG_ LH1_text_bits : 10|3@1+ (1,0) [0|7] "" XXX
 SG_ LH1_acoustic_signal : 13|1@1+ (1,0) [0|1] "" XXX
 SG_ LH1_SleepInd : 14|1@1+ (1,0) [0|1] "" XXX
 SG_ LH1_error_entry : 15|1@1+ (1,0) [0|1] "" XXX
 SG_ LH1_EPS_diag_mode : 16|1@1+ (1,0) [0|1] "" XXX
 SG_ LH1_gue_ECU_temp : 19|1@1+ (1,0) [0|1] "" XXX
 SG_ LH1_cooling : 20|1@1+ (1,0) [0|1] "" XXX
 SG_ LH1_mode_hybrid : 21|1@1+ (1,0) [0|1] "" XXX
 SG_ LH1_NL_undervoltage : 24|1@1+ (1,0) [0|1] "" XXX
 SG_ LH1_NL_overvoltage : 25|1@1+ (1,0) [0|1] "" XXX
 SG_ LH1_NL_overtemp : 26|1@1+ (1,0) [0|1] "" XXX
 SG_ LH1_NL_sensor : 27|1@1+ (1,0) [0|1] "" XXX
 SG_ LH1_NL_CAN_SS : 28|1@1+ (1,0) [0|1] "" XXX
 SG_ LH1_NL_ECU : 29|1@1+ (1,0) [0|1] "" XXX
 SG_ LH1_NL_motor : 30|1@1+ (1,0) [0|1] "" XXX
 SG_ LH1_NL_power_density : 31|1@1+ (1,0) [0|1] "" XXX
 SG_ LH1_U_power : 32|8@1+ (0.5,0) [0|100] "%" XXX
 SG_ LH1_ECU_temp : 40|8@1+ (1,-70) [-70|185] "°C" XXX

BO_ 1312 instrument_cluster_3: 8 XXX
 SG_ free_cluster_3_2 : 60|4@1+ (1,0) [0|0] "" XXX
 SG_ odometer : 40|20@1+ (1,0) [0|1000000] "km" XXX
 SG_ fault_status_standstill_time : 39|1@1+ (1,0) [0|0] "" XXX
 SG_ standstill_time : 24|15@1+ (4,0) [0|131068] "sec" XXX
 SG_ free_cluster_3_1 : 20|4@1+ (1,0) [0|0] "" XXX
 SG_ key_info : 16|4@1+ (1,0) [0|15] "" XXX
 SG_ instrument_cluster_Multiplex_Code M : 14|2@1+ (1,0) [0|0] "" XXX
 SG_ Kombi_installation_list_level_control m3 : 11|1@1+ (1,0) [0|0] "" XXX
 SG_ instrument_cluster_Multiplex_brand m1 : 11|3@1+ (1,0) [0|0] "" XXX
 SG_ Kombi_installation_list_steering_assist m3 : 10|1@1+ (1,0) [0|0] "" XXX
 SG_ Kombi_installation_list_diesel_pump m3 : 9|1@1+ (1,0) [0|0] "" XXX
 SG_ Kombi_installation_list_steering_angle m3 : 8|1@1+ (1,0) [0|0] "" XXX
 SG_ instrument_cluster_Multiplex_series m1 : 8|3@1+ (1,0) [0|0] "" XXX
 SG_ instrument_cluster_Multiplex_country_variant m0 : 8|6@1+ (1,0) [0|0] "" XXX
 SG_ Kombi_installation_list_all_wheel_drive m3 : 7|1@1+ (1,0) [0|0] "" XXX
 SG_ Kombi_installation_list_electrical_system m3 : 6|1@1+ (1,0) [0|0] "" XXX
 SG_ Kombi_installation_list_ACC m3 : 5|1@1+ (1,0) [0|0] "" XXX
 SG_ Kombi_installation_list_airbag m3 : 4|1@1+ (1,0) [0|0] "" XXX
 SG_ instrument_cluster_Multiplex_generation m1 : 4|4@1+ (1,0) [0|0] "" XXX
 SG_ Kombi_installation_list_climate m3 : 3|1@1+ (1,0) [0|0] "" XXX
 SG_ instrument_cluster_installation_list_ABS m3 : 2|1@1+ (1,0) [0|0] "" XXX
 SG_ Kombi_installation_list_engine m3 : 0|1@1+ (1,0) [0|0] "" XXX
 SG_ instrument_cluster_Multiplex_derivative m1 : 0|4@1+ (1,0) [0|0] "" XXX
 SG_ instrument_cluster_Multiplex_language_variant m0 : 0|8@1+ (1,0) [0|0] "" XXX
 SG_ instrument_cluster_Multiplex_tire_circumference m2 : 0|12@1+ (1,0) [0|4095] "mm" XXX

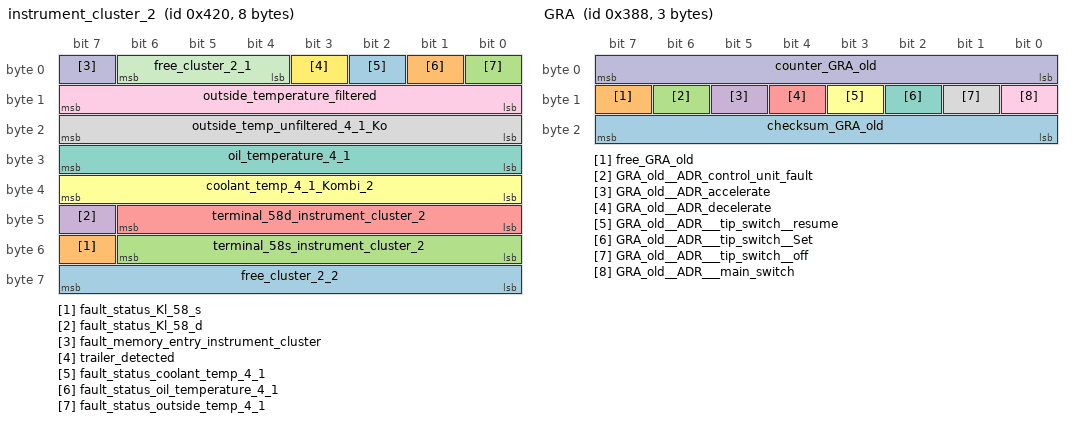
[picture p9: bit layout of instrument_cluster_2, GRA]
BO_ 1056 instrument_cluster_2: 8 XXX
 SG_ free_cluster_2_2 : 56|8@1+ (1,0) [0|0] "" XXX
 SG_ fault_status_Kl_58_s : 55|1@1+ (1,0) [0|0] "" XXX
 SG_ terminal_58s_instrument_cluster_2 : 48|7@1+ (1,0) [0|100] "%" XXX
 SG_ fault_status_Kl_58_d : 47|1@1+ (1,0) [0|0] "" XXX
 SG_ terminal_58d_instrument_cluster_2 : 40|7@1+ (1,0) [0|100] "%" XXX
 SG_ coolant_temp_4_1_Kombi_2 : 32|8@1+ (0.75,-48) [-48|142.5] "C" XXX
 SG_ oil_temperature_4_1 : 24|8@1+ (1,-60) [-60|194] "C" XXX
 SG_ outside_temp_unfiltered_4_1_Ko : 16|8@1+ (0.5,-50) [-50|77] "C" XXX
 SG_ outside_temperature_filtered : 8|8@1+ (0.5,-50) [-50|77] "C" XXX
 SG_ fault_memory_entry_instrument_cluster : 7|1@1+ (1,0) [0|0] "" XXX
 SG_ free_cluster_2_1 : 4|3@1+ (1,0) [0|0] "" XXX
 SG_ trailer_detected : 3|1@1+ (1,0) [0|0] "" XXX
 SG_ fault_status_coolant_temp_4_1 : 2|1@1+ (1,0) [0|0] "" XXX
 SG_ fault_status_oil_temperature_4_1 : 1|1@1+ (1,0) [0|0] "" XXX
 SG_ fault_status_outside_temp_4_1 : 0|1@1+ (1,0) [0|0] "" XXX

BO_ 800 instrument_cluster_1: 8 XXX
 SG_ free_cluster_1_3 : 56|8@1+ (1,0) [0|0] "" XXX
 SG_ displayed_speed : 46|10@1+ (0.32,0) [0|325] "km/h" XXX
 SG_ turn_signal_right_4_1 : 45|1@1+ (1,0) [0|0] "" XXX
 SG_ turn_signal_left_4_1 : 44|1@1+ (1,0) [0|0] "" XXX
 SG_ set_time_gap__cluster_1_ : 43|1@1+ (1,0) [0|0] "" XXX
 SG_ ADR_buzzer_switched_off : 42|1@1+ (1,0) [0|0] "" XXX
 SG_ free_cluster_1_2 : 40|2@1+ (1,0) [0|0] "" XXX
 SG_ speed__cluster_1_ : 25|15@1+ (0.01,0) [0|326] "km/h" XXX
 SG_ signal_source_speed_4_ : 24|1@1+ (1,0) [0|0] "" XXX
 SG_ fuel_warning : 23|1@1+ (1,0) [0|0] "" XXX
 SG_ fuel_tank_content : 16|7@1+ (1,0) [0|126] "l" XXX
 SG_ fuel_stop : 15|1@1+ (1,0) [0|0] "" XXX
 SG_ free_cluster_1_7 : 12|3@1+ (1,0) [0|0] "" XXX
 SG_ Kombi_in_actuator_test : 11|1@1+ (1,0) [0|0] "" XXX
 SG_ charge_indicator_lamp__instrument_cluster_ : 10|1@1+ (1,0) [0|0] "" XXX
 SG_ brake_info : 8|2@1+ (1,0) [0|0] "" XXX
 SG_ preheat_lamp__Kombi_1_ : 7|1@1+ (1,0) [0|0] "" XXX
 SG_ fuel_warning_lamp : 6|1@1+ (1,0) [0|0] "" XXX
 SG_ hot_glow_prewarning : 5|1@1+ (1,0) [0|0] "" XXX
 SG_ coolant_shortage : 4|1@1+ (1,0) [0|0] "" XXX
 SG_ dynamic_oil_pressure_warning : 3|1@1+ (1,0) [0|0] "" XXX
 SG_ oil_pressure : 2|1@1+ (1,0) [0|0] "" XXX
 SG_ fault_status_tank : 1|1@1+ (1,0) [0|0] "" XXX
 SG_ driver_door_4_1 : 0|1@1+ (1,0) [0|0] "" XXX

BO_ 1504 climate_1: 8 XXX
 SG_ outside_temp_approx_disturb__4_1 : 56|8@1+ (0.5,-50) [-50|77] "C" XXX
 SG_ fault_memory_entry_climate : 55|1@1+ (1,0) [0|0] "" XXX
 SG_ free_climate_1_5 : 50|5@1+ (1,0) [0|0] "" XXX
 SG_ AC_switch : 49|1@1+ (1,0) [0|0] "" XXX
 SG_ temperature_unit : 48|1@1+ (1,0) [0|0] "" XXX
 SG_ radiator_fan_control_climate : 40|8@1+ (0.4,0) [0|101.6] "%" XXX
 SG_ blower_load_4_1 : 32|8@1+ (0.4,0) [0|101.6] "%" XXX
 SG_ compressor_load : 24|8@1+ (0.25,0) [0|63.5] "Nm" XXX
 SG_ climate_pressure_signal_climate_1 : 16|8@1+ (0.2,0) [0|50.8] "bar" XXX
 SG_ outside_temp_approx__4_1__climate_1 : 8|8@1+ (0.5,-50) [-50|77] "C" XXX
 SG_ refrigerant_pressure_outdated : 7|1@1+ (1,0) [0|0] "" XXX
 SG_ compressor_torque_obsolete_4_1 : 6|1@1+ (1,0) [0|0] "" XXX
 SG_ no_heating_power_desired_4_1 : 5|1@1+ (1,0) [0|0] "" XXX
 SG_ compressor_state_4_1 : 4|1@1+ (1,0) [0|0] "" XXX
 SG_ heatable_windshield : 3|1@1+ (1,0) [0|0] "" XXX
 SG_ heatable_rear_window : 2|1@1+ (1,0) [0|0] "" XXX
 SG_ driver_desired_auxiliary_heater : 1|1@1+ (1,0) [0|0] "" XXX
 SG_ rpm_increase : 0|1@1+ (1,0) [0|0] "" XXX

BO_ 906 GRA_new: 4 XXX
 SG_ CHECKSUM : 0|8@1+ (1,0) [0|255] "" XXX
 SG_ GRA_main_switch : 8|1@1+ (1,0) [0|1] "" XXX
 SG_ GRA_cancel : 9|1@1+ (1,0) [0|1] "" XXX
 SG_ GRA_Down_short : 10|1@1+ (1,0) [0|1] "" XXX
 SG_ GRA_Up_short : 11|1@1+ (1,0) [0|1] "" XXX
 SG_ GRA_Down_long : 12|1@1+ (1,0) [0|1] "" XXX
 SG_ GRA_Up_long : 13|1@1+ (1,0) [0|1] "" XXX
 SG_ GRA_fault_operation : 14|1@1+ (1,0) [0|1] "" XXX
 SG_ GRA_coding_info : 15|1@1+ (1,0) [0|1] "" XXX
 SG_ GRA_new_set : 16|1@1+ (1,0) [0|1] "" XXX
 SG_ GRA_Recall : 17|1@1+ (1,0) [0|1] "" XXX
 SG_ GRA_transmitter : 18|2@1+ (1,0) [0|3] "" XXX
 SG_ COUNTER : 20|4@1+ (1,0) [0|15] "" XXX
 SG_ GRA_Tip_Down : 24|1@1+ (1,0) [0|1] "" XXX
 SG_ GRA_Tip_Up : 25|1@1+ (1,0) [0|1] "" XXX
 SG_ GRA_time_gap : 26|2@1+ (1,0) [0|3] "" XXX
 SG_ GRA_Sta_Limiter : 28|1@1+ (1,0) [0|1] "" XXX
 SG_ GRA_type_main_switch : 29|1@1+ (1,0) [0|1] "" XXX
 SG_ GRA_sport_switch : 30|1@1+ (1,0) [0|1] "" XXX
 SG_ GRA_fault_tip : 31|1@1+ (1,0) [0|1] "" XXX

BO_ 904 GRA: 3 XXX
 SG_ checksum_GRA_old : 16|8@1+ (1,0) [0|0] "" XXX
 SG_ free_GRA_old : 15|1@1+ (1,0) [0|0] "" XXX
 SG_ GRA_old__ADR_control_unit_fault : 14|1@1+ (1,0) [0|0] "" XXX
 SG_ GRA_old__ADR_accelerate : 13|1@1+ (1,0) [0|0] "" XXX
 SG_ GRA_old__ADR_decelerate : 12|1@1+ (1,0) [0|0] "" XXX
 SG_ GRA_old__ADR___tip_switch__resume : 11|1@1+ (1,0) [0|0] "" XXX
 SG_ GRA_old__ADR___tip_switch__Set : 10|1@1+ (1,0) [0|0] "" XXX
 SG_ GRA_old__ADR___tip_switch__off : 9|1@1+ (1,0) [0|0] "" XXX
 SG_ GRA_old__ADR___main_switch : 8|1@1+ (1,0) [0|0] "" XXX
 SG_ counter_GRA_old : 0|8@1+ (1,0) [0|255] "" XXX

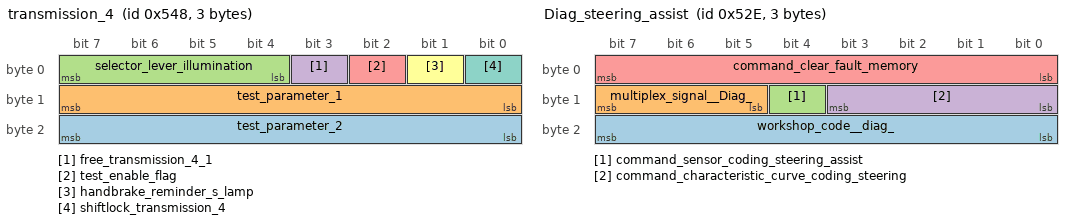
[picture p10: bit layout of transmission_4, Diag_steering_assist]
BO_ 1352 transmission_4: 3 XXX
 SG_ test_parameter_2 : 16|8@1+ (1,0) [0|255] "" XXX
 SG_ test_parameter_1 : 8|8@1+ (1,0) [0|255] "" XXX
 SG_ selector_lever_illumination : 4|4@1+ (1,0) [0|0] "" XXX
 SG_ free_transmission_4_1 : 3|1@1+ (1,0) [0|0] "" XXX
 SG_ test_enable_flag : 2|1@1+ (1,0) [0|0] "" XXX
 SG_ handbrake_reminder_s_lamp : 1|1@1+ (1,0) [0|0] "" XXX
 SG_ shiftlock_transmission_4 : 0|1@1+ (1,0) [0|0] "" XXX

BO_ 1344 transmission_2: 8 XXX
 SG_ engaged_gear : 60|4@1+ (1,0) [0|0] "" XXX
 SG_ gear_display_cluster___transmission_Va : 56|4@1+ (1,0) [0|15] "" XXX
 SG_ fault_lamp_for_clutch_at_VL : 55|1@1+ (1,0) [0|0] "" XXX
 SG_ request_creep_adaptation : 54|1@1+ (1,0) [0|0] "" XXX
 SG_ ECO_display_4_1 : 53|1@1+ (1,0) [0|0] "" XXX
 SG_ Shift_Lock_lamp : 52|1@1+ (1,0) [0|0] "" XXX
 SG_ suppression_of_warnings : 51|1@1+ (1,0) [0|0] "" XXX
 SG_ chime : 50|1@1+ (1,0) [0|0] "" XXX
 SG_ starter_being_controlled : 49|1@1+ (1,0) [0|0] "" XXX
 SG_ upshift_lamp : 48|1@1+ (1,0) [0|0] "" XXX
 SG_ synchronization_time : 40|8@1+ (20,0) [0|5080] "ms" XXX
 SG_ inverted_synchronization_desired : 32|8@1+ (25,0) [0|6350] "U/min" XXX
 SG_ synchronization_desired_rpm : 24|8@1+ (25,0) [0|6350] "U/min" XXX
 SG_ gradient_limit : 16|8@1+ (10,0) [0|2540] "Nm/s" XXX
 SG_ idle_target_rpm_transmission : 8|8@1+ (10,0) [0|2540] "U/min" XXX
 SG_ counter_transmission_2 : 4|4@1+ (1,0) [0|15] "" XXX
 SG_ throttle_blip_flag : 3|1@1+ (1,0) [0|0] "" XXX
 SG_ Ecomatic__4_1_ : 2|1@1+ (1,0) [0|0] "" XXX
 SG_ fuel_cutoff_support : 1|1@1+ (1,0) [0|0] "" XXX
 SG_ LFR_adaptation_enable_flag : 0|1@1+ (1,0) [0|0] "" XXX

BO_ 1088 transmission_1: 8 Transmission
 SG_ GE1_shifting : 0|1@1+ (1,0) [0|1] "" Gateway
 SG_ GE1_status_protection : 1|1@1+ (1,0) [0|1] "" engine
 SG_ GE1_AC_compressor : 2|1@1+ (1,0) [0|1] "" engine
 SG_ GE1_WK : 3|2@1+ (1,0) [0|3] "" Gateway
 SG_ GE1_StSt_info : 5|2@1+ (1,0) [0|3] "" Gateway
 SG_ GE1_EGS_request : 7|1@1+ (1,0) [0|1] "" engine
 SG_ GE1_target_gear : 8|4@1+ (1,0) [0|15] "" Gateway
 SG_ GE1_selection_Pos : 12|4@1+ (1,0) [0|15] "" Gateway
 SG_ GE1_Mrad_Mkurb : 16|8@1+ (0.1,0) [0|25.4] "" Gateway
 SG_ GE1_target_Mo : 24|8@1+ (0.39,0) [0|99.06] "%" engine
 SG_ GE1_Fahrwistd : 32|8@1+ (0.249,-31.623) [-31.623|31.623] "" Gateway
 SG_ GE1_limp_home : 40|4@1+ (1,0) [0|15] "" Gateway
 SG_ GE1_cooling : 44|2@1+ (1,0) [0|3] "" Gateway
 SG_ GE1_status_OBD : 47|1@1+ (1,0) [0|1] "" engine
 SG_ GE1_LaunchControl : 48|1@1+ (1,0) [0|1] "" ESP
 SG_ GE1_info_bit : 49|1@1+ (1,0) [0|1] "" Gateway
 SG_ GE1_SleepInd : 50|1@1+ (1,0) [0|1] "" Gateway
 SG_ COUNTER : 51|4@1+ (1,0) [0|15] "" Gateway
 SG_ GE1_fault_entry : 55|1@1+ (1,0) [0|1] "" Gateway
 SG_ GE1_WaVerl_Mo : 56|8@1+ (0.39,0) [0|99.06] "%" engine

BO_ 912 gate_comfort_1: 8 XXX
 SG_ GK1_Sta_RDK_warning : 0|1@1+ (1,0) [0|1] "" XXX
 SG_ GK1_Sta_trailer : 1|1@1+ (1,0) [0|1] "" XXX
 SG_ GK1_Sta_light1 : 2|1@1+ (1,0) [0|1] "" XXX
 SG_ GK1_Sta_light3 : 3|1@1+ (1,0) [0|1] "" XXX
 SG_ GK1_Sta_door_contact : 4|1@1+ (1,0) [0|1] "" XXX
 SG_ GK1_Sta_Li_front : 5|1@1+ (1,0) [0|1] "" XXX
 SG_ GK1_SleepAckn : 7|1@1+ (1,0) [0|1] "" XXX
 SG_ GK1_charisma_mode m1 : 8|4@1+ (1,0) [0|15] "" XXX
 SG_ GK1_Sam_function_number M : 12|4@1+ (1,0) [0|15] "" XXX
 SG_ GK1_driver_door_contact : 16|1@1+ (1,0) [0|1] "" XXX
 SG_ GK1_reverse_light : 17|1@1+ (1,0) [0|1] "" XXX
 SG_ GK1_ELV_locked : 18|1@1+ (1,0) [0|1] "" XXX
 SG_ GK1_Sta_Kessy_2 : 19|1@1+ (1,0) [0|1] "" XXX
 SG_ GK1_Sta_auxiliary_heater : 20|1@1+ (1,0) [0|1] "" XXX
 SG_ GK1_SH_installation : 21|1@1+ (1,0) [0|1] "" XXX
 SG_ GK1_park_front_wiper : 22|1@1+ (1,0) [0|1] "" XXX
 SG_ GK1_KW_warm : 23|1@1+ (1,0) [0|1] "" XXX
 SG_ BCM_remote_start_operation : 24|1@1+ (1,0) [0|1] "" XXX
 SG_ BSK_HL_opened : 26|1@1+ (1,0) [0|1] "" XXX
 SG_ BSK_HR_opened : 27|1@1+ (1,0) [0|1] "" XXX
 SG_ GK1_reverse : 28|1@1+ (1,0) [0|1] "" XXX
 SG_ GK1_brake_light_left : 29|1@1+ (1,0) [0|1] "" XXX
 SG_ GK1_brake_light_right : 30|1@1+ (1,0) [0|1] "" XXX
 SG_ GK1_brake_light_center : 31|1@1+ (1,0) [0|1] "" XXX
 SG_ GK1_BLS_ILM : 32|1@1+ (1,0) [0|1] "" XXX
 SG_ GK1_EDC_ILM : 33|1@1+ (1,0) [0|1] "" XXX
 SG_ GK1_turn_signal_left : 34|1@1+ (1,0) [0|1] "" XXX
 SG_ GK1_turn_signal_right : 35|1@1+ (1,0) [0|1] "" XXX
 SG_ GK1_def_P_locked : 36|1@1+ (1,0) [0|1] "" XXX
 SG_ GK1_LS1_high_beam : 37|1@1+ (1,0) [0|1] "" XXX
 SG_ GK1_Sta_light2 : 38|1@1+ (1,0) [0|1] "" XXX
 SG_ GK1_Sta_LSM : 39|1@1+ (1,0) [0|1] "" XXX
 SG_ GK1_Count_trailer : 40|4@1+ (1,0) [0|15] "" XXX
 SG_ BSK_BT_opened : 41|1@1+ (1,0) [0|1] "" XXX
 SG_ BSK_HD_main_detent : 43|1@1+ (1,0) [0|1] "" XXX
 SG_ GK1_BLS_AAG : 44|1@1+ (1,0) [0|1] "" XXX
 SG_ GK1_EDC_AAG : 45|1@1+ (1,0) [0|1] "" XXX
 SG_ GK1_trailer : 46|1@1+ (1,0) [0|1] "" XXX
 SG_ GK1_brake_light_trailer : 47|1@1+ (1,0) [0|1] "" XXX
 SG_ GK1_low_beam : 48|1@1+ (1,0) [0|1] "" XXX
 SG_ GK1_high_beam : 49|1@1+ (1,0) [0|1] "" XXX
 SG_ GK1_wiper_front : 50|1@1+ (1,0) [0|1] "" XXX
 SG_ GK1_Sta_ILM_F_1 : 51|1@1+ (1,0) [0|1] "" XXX
 SG_ GK1_low_beam_VL_def : 52|1@1+ (1,0) [0|1] "" XXX
 SG_ GK1_low_beam_VR_def : 53|1@1+ (1,0) [0|1] "" XXX
 SG_ GK1_turn_signal_highway : 54|1@1+ (1,0) [0|1] "" XXX
 SG_ GK1_hazard_lights_status : 55|1@1+ (1,0) [0|1] "" XXX
 SG_ GK1_SH_running : 56|1@1+ (1,0) [0|1] "" XXX
 SG_ SH1_on_water_pump : 57|1@1+ (1,0) [0|1] "" XXX
 SG_ GK1_fog_on : 58|1@1+ (1,0) [0|1] "" XXX
 SG_ GK1_brake_light : 59|1@1+ (1,0) [0|1] "" XXX
 SG_ GK1_trailer_disconnected : 60|1@1+ (1,0) [0|1] "" XXX
 SG_ GK1_trailer_control_lamp : 61|1@1+ (1,0) [0|1] "" XXX
 SG_ LDS_position_AFL : 62|1@1+ (1,0) [0|1] "" XXX
 SG_ GK1_SH_additional_function : 63|1@1+ (1,0) [0|1] "" XXX

BO_ 1340 chassis_1: 1 XXX
 SG_ free_chassis_1_2 : 7|1@1+ (1,0) [0|0] "" XXX
 SG_ free_chassis_1_1 : 6|2@1+ (1,0) [0|0] "" XXX
 SG_ setting_chassis_damping_4 : 4|3@1+ (1,0) [0|7] "" XXX
 SG_ control_vehicle_level : 0|4@1+ (1,0) [0|15] "" XXX

BO_ 1472 EPB_1: 8 XXX
 SG_ COUNTER : 0|4@1+ (1,0) [0|15] "" XXX
 SG_ EP1_fault_status : 4|2@1+ (1,0) [0|3] "" Vector__XXX
 SG_ EP1_status_EPB : 6|1@1+ (1,0) [0|1] "" XXX
 SG_ EP1_status_switch : 7|1@1+ (1,0) [0|1] "" XXX
 SG_ EP1_clamping_force : 8|5@1+ (1,0) [0|30] "Unit_KiloNewto" XXX
 SG_ EP1_switch_info : 13|2@1+ (1,0) [0|3] "" XXX
 SG_ EP1_status_NWS : 15|1@1+ (1,0) [0|1] "" XXX
 SG_ EP1_Neig_angle : 16|8@1+ (1,-128) [-128|127] "Unit_PerCentOfForceOfGravi" XXX
 SG_ EP1_deceleration : 24|8@1+ (0.048,-7.968) [-7.968|4.224] "Unit_MeterPerSeconSquar" XXX
 SG_ EP1_fault_entry : 32|1@1+ (1,0) [0|1] "" XXX
 SG_ EP1_release_Ver : 33|1@1+ (1,0) [0|1] "" XXX
 SG_ EP1_AutoHold_allowed : 34|1@1+ (1,0) [0|1] "" XXX
 SG_ EP1_AutoHold_active : 35|1@1+ (1,0) [0|1] "" XXX
 SG_ EP1_SleepInd : 36|1@1+ (1,0) [0|1] "" XXX
 SG_ EP1_status_Kl_15 : 37|1@1+ (1,0) [0|1] "" XXX
 SG_ EP1_lamp_AutoP : 38|1@1+ (1,0) [0|1] "" XXX
 SG_ EP1_brake_light : 39|1@1+ (1,0) [0|1] "" XXX
 SG_ EP1_warning_tone1 : 40|1@1+ (1,0) [0|1] "" XXX
 SG_ EP1_warning_tone2 : 41|1@1+ (1,0) [0|1] "" XXX
 SG_ EP1_request_ShLock : 42|1@1+ (1,0) [0|1] "" XXX
 SG_ EPB_autohold_lamp : 43|1@1+ (1,0) [0|1] "" XXX
 SG_ EP1_QualNeigWi : 44|1@1+ (1,0) [0|1] "" XXX
 SG_ EP1_KuppModBer : 45|2@1+ (1,0) [0|3] "" XXX
 SG_ EP1_HydrHold : 47|1@1+ (1,0) [0|1] "" XXX
 SG_ EP1_function_lamp : 48|1@1+ (1,0) [0|1] "" Vector__XXX
 SG_ EP1_warning_tone : 49|1@1+ (1,0) [0|1] "" XXX
 SG_ EP1_fault_BKL : 50|1@1+ (1,0) [0|1] "" Vector__XXX
 SG_ EP1_fault_yellow : 51|1@1+ (1,0) [0|1] "" XXX
 SG_ EP1__text : 52|4@1+ (1,0) [0|8] "" Vector__XXX
 SG_ CHECKSUM : 56|8@1+ (1,0) [0|255] "" XXX

BO_ 1326 Diag_steering_assist: 3 XXX
 SG_ workshop_code__diag_ : 16|8@1+ (1,0) [0|0] "" XXX
 SG_ multiplex_signal__Diag_ : 13|3@1+ (1,0) [0|7] "" XXX
 SG_ command_sensor_coding_steering_assist : 12|1@1+ (1,0) [0|0] "" XXX
 SG_ command_characteristic_curve_coding_steering : 8|4@1+ (1,0) [0|0] "" XXX
 SG_ command_clear_fault_memory : 0|8@1+ (1,0) [0|0] "" XXX

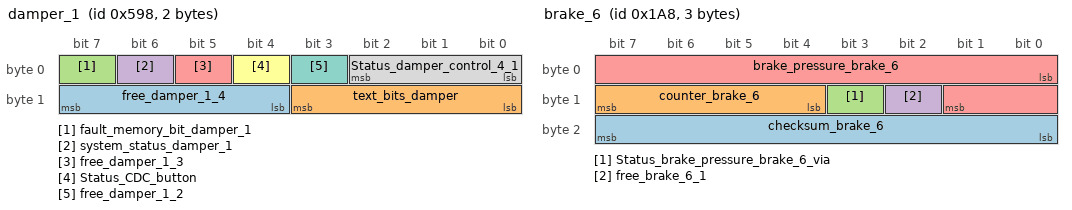
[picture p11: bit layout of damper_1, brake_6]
BO_ 1432 damper_1: 2 XXX
 SG_ free_damper_1_4 : 12|4@1+ (1,0) [0|0] "" XXX
 SG_ text_bits_damper : 8|4@1+ (1,0) [0|0] "" XXX
 SG_ fault_memory_bit_damper_1 : 7|1@1+ (1,0) [0|0] "" XXX
 SG_ system_status_damper_1 : 6|1@1+ (1,0) [0|0] "" XXX
 SG_ free_damper_1_3 : 5|1@1+ (1,0) [0|0] "" XXX
 SG_ Status_CDC_button : 4|1@1+ (1,0) [0|0] "" XXX
 SG_ free_damper_1_2 : 3|1@1+ (1,0) [0|0] "" XXX
 SG_ Status_damper_control_4_1 : 0|3@1+ (1,0) [0|7] "" XXX

BO_ 1392 BSG_load: 4 XXX
 SG_ air_conditioning_shut_off : 31|1@1+ (1,0) [0|0] "" XXX
 SG_ seat_ventilation_switch_off : 30|1@1+ (1,0) [0|0] "" XXX
 SG_ washer_water_heater_switch_off : 29|1@1+ (1,0) [0|0] "" XXX
 SG_ steering_wheel_heating_switch_off : 28|1@1+ (1,0) [0|0] "" XXX
 SG_ heatable_seats_shutoff : 27|1@1+ (1,0) [0|0] "" XXX
 SG_ heatable_exterior_mirror_shutoff : 26|1@1+ (1,0) [0|0] "" XXX
 SG_ heatable_windshield_shutoff : 25|1@1+ (1,0) [0|0] "" XXX
 SG_ heatable_rear_window_shutoff : 24|1@1+ (1,0) [0|0] "" XXX
 SG_ battery_voltage_onboard_supply_battery : 16|8@1+ (0.05,5) [5|17.7] "V" XXX
 SG_ engine_hood_contact : 15|1@1+ (1,0) [0|0] "" XXX
 SG_ headlight_range_control : 14|1@1+ (1,0) [0|0] "" XXX
 SG_ fault_memory_entry_BSG_load : 13|1@1+ (1,0) [0|0] "" XXX
 SG_ state_of_starter_battery : 11|2@1+ (1,0) [0|0] "" XXX
 SG_ state_of_onboard_power_battery : 9|2@1+ (1,0) [0|0] "" XXX
 SG_ LL_rpm_increase : 8|1@1+ (1,0) [0|0] "" XXX
 SG_ terminal_L : 7|1@1+ (1,0) [0|0] "" XXX
 SG_ free_BSG_load_1_1 : 4|3@1+ (1,0) [0|0] "" XXX
 SG_ ZAS_terminal_50 : 3|1@1+ (1,0) [0|0] "" XXX
 SG_ ZAS_terminal_X : 2|1@1+ (1,0) [0|0] "" XXX
 SG_ ZAS_terminal_15 : 1|1@1+ (1,0) [0|0] "" XXX
 SG_ ZAS_terminal_S : 0|1@1+ (1,0) [0|0] "" XXX

BO_ 1136 BSG_cluster: 5 XXX
 SG_ free_BSG_instrument_cluster_1_3 : 36|4@1+ (1,0) [0|0] "" XXX
 SG_ rear_seat_backrest_HR_locked_4_1 : 35|1@1+ (1,0) [0|0] "" XXX
 SG_ rear_seat_backrest_HL_locked_4_1 : 34|1@1+ (1,0) [0|0] "" XXX
 SG_ fault_lamp_steering_assist_outdated : 33|1@1+ (1,0) [0|0] "" XXX
 SG_ fault_lamp_steering_assist_BSG_Komb : 32|1@1+ (1,0) [0|0] "" XXX
 SG_ fault_status_Kl_58s : 31|1@1+ (1,0) [0|0] "" XXX
 SG_ terminal_58s_BSG_instrument_cluster : 24|7@1+ (1,0) [0|100] "%" XXX
 SG_ fault_status_Kl_58d : 23|1@1+ (1,0) [0|0] "" XXX
 SG_ terminal_58d_BSG_instrument_cluster : 16|7@1+ (1,0) [0|100] "%" XXX
 SG_ undervoltage : 15|1@1+ (1,0) [0|0] "" XXX
 SG_ free_BSG_instrument_cluster_1_2 : 14|1@1+ (1,0) [0|0] "" XXX
 SG_ tailgate_opened : 13|1@1+ (1,0) [0|0] "" XXX
 SG_ engine_hood_open : 12|1@1+ (1,0) [0|0] "" XXX
 SG_ door_rear_right_opened : 11|1@1+ (1,0) [0|0] "" XXX
 SG_ door_rear_left_opened : 10|1@1+ (1,0) [0|0] "" XXX
 SG_ passenger_door_opened : 9|1@1+ (1,0) [0|0] "" XXX
 SG_ driver_door_opened : 8|1@1+ (1,0) [0|0] "" XXX
 SG_ charge_indicator_lamp : 7|1@1+ (1,0) [0|0] "" XXX
 SG_ free_BSG_instrument_cluster_1_1 : 6|1@1+ (1,0) [0|0] "" XXX
 SG_ reversing_light : 5|1@1+ (1,0) [0|0] "" XXX
 SG_ DWA_battery : 4|1@1+ (1,0) [0|0] "" XXX
 SG_ hazard_flash_Mode : 3|1@1+ (1,0) [0|0] "" XXX
 SG_ trailer_indicator_lamp : 2|1@1+ (1,0) [0|0] "" XXX
 SG_ turn_signal_right_indicator_lamp : 1|1@1+ (1,0) [0|0] "" XXX
 SG_ turn_signal_left_indicator_lamp : 0|1@1+ (1,0) [0|0] "" XXX

BO_ 424 brake_6: 3 XXX
 SG_ checksum_brake_6 : 16|8@1+ (1,0) [0|0] "" XXX
 SG_ counter_brake_6 : 12|4@1+ (1,0) [0|15] "" XXX
 SG_ Status_brake_pressure_brake_6_via : 11|1@1+ (1,0) [0|0] "" XXX
 SG_ free_brake_6_1 : 10|1@1+ (1,0) [0|0] "" XXX
 SG_ brake_pressure_brake_6 : 0|10@1+ (0.3255,-40) [-40|293] "bar" XXX

BO_ 1192 brake_5: 8 XXX
 SG_ CHECKSUM : 56|8@1+ (1,0) [0|0] "" XXX
 SG_ COUNTER : 52|4@1+ (1,0) [0|15] "" XXX
 SG_ BR5_ECD_lamp : 51|1@1+ (1,0) [0|0] "" XXX
 SG_ BR5_ZT_feedback_conversion : 48|1@1+ (1,0) [0|1] "" XXX
 SG_ BR5_hold_status : 40|1@1+ (1,0) [0|1] "" XXX
 SG_ ESP_roller_mode_deactivate : 34|1@1+ (1,0) [0|1] "" XXX
 SG_ BR5_sign_pressure : 31|1@1+ (1,0) [0|1] "" XXX
 SG_ BR5_status_pressure : 30|1@1+ (1,0) [0|1] "" XXX
 SG_ BR5_pressure_valid : 29|1@1+ (1,0) [0|1] "" XXX
 SG_ BR5_standstill : 28|1@1+ (1,0) [0|1] "" XXX
 SG_ BR5_brake_pressure : 16|12@1+ (0.1,0) [0|250] "bar" XXX
 SG_ BR5_sign : 15|1@1+ (1,0) [0|1] "" XXX
 SG_ BR5_status_yaw_rate : 14|1@1+ (1,0) [0|1] "" XXX
 SG_ BR5_yaw_rate : 0|14@1+ (0.01,0) [0|100] "Grad/sec" XXX
 SG_ BR5_ANB_CM_feedback_conversion : 49|1@1+ (1,0) [0|1] "" XXX
 SG_ BR5_HDC_ready : 50|1@1+ (1,0) [0|1] "" XXX
 SG_ ESP_status_FallBack_eBKV : 35|1@1+ (1,0) [0|1] "" XXX
 SG_ ESP_request_EPB : 36|2@1+ (1,0) [0|3] "" XXX
 SG_ ESP_autohold_active : 38|1@1+ (1,0) [0|1] "" XXX
 SG_ ESP_Autohold_Standby : 39|1@1+ (1,0) [0|1] "" XXX
 SG_ BR5_hold_active : 41|1@1+ (1,0) [0|1] "" XXX
 SG_ BR5_v_monitoring : 42|1@1+ (1,0) [0|1] "" XXX
 SG_ BR5_brake_light : 43|1@1+ (1,0) [0|1] "" XXX
 SG_ BR5_emergency_braking : 44|1@1+ (1,0) [0|1] "" XXX
 SG_ BR5_driver_presses_ZBR_threshold : 45|1@1+ (1,0) [0|1] "" XXX
 SG_ BR5_AWV2_brake_jerk : 46|1@1+ (1,0) [0|1] "" XXX
 SG_ BR5_AWV2_fault : 47|1@1+ (1,0) [0|1] "" XXX

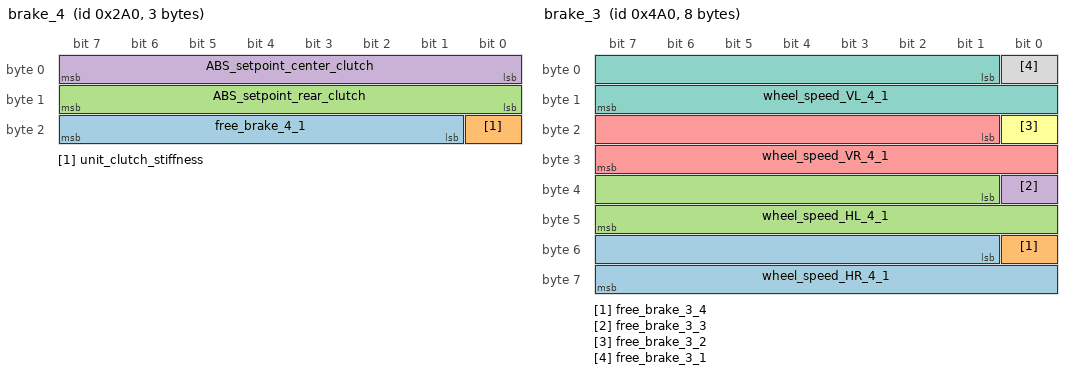
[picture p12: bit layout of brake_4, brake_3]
BO_ 672 brake_4: 3 XXX
 SG_ free_brake_4_1 : 17|7@1+ (1,0) [0|0] "" XXX
 SG_ unit_clutch_stiffness : 16|1@1+ (1,0) [0|0] "" XXX
 SG_ ABS_setpoint_rear_clutch : 8|8@1+ (0.7874,0) [0|100] "%" XXX
 SG_ ABS_setpoint_center_clutch : 0|8@1+ (3,-381) [-381|378] "Nm/min" XXX

BO_ 1184 brake_3: 8 XXX
 SG_ wheel_speed_HR_4_1 : 49|15@1+ (0.01,0) [0|326] "km/h" XXX
 SG_ free_brake_3_4 : 48|1@1+ (1,0) [0|0] "" XXX
 SG_ wheel_speed_HL_4_1 : 33|15@1+ (0.01,0) [0|326] "km/h" XXX
 SG_ free_brake_3_3 : 32|1@1+ (1,0) [0|0] "" XXX
 SG_ wheel_speed_VR_4_1 : 17|15@1+ (0.01,0) [0|326] "km/h" XXX
 SG_ free_brake_3_2 : 16|1@1+ (0.01,0) [0|325] "km/h" XXX
 SG_ wheel_speed_VL_4_1 : 1|15@1+ (0.01,0) [0|326] "km/h" XXX
 SG_ free_brake_3_1 : 0|1@1+ (1,0) [0|0] "" XXX

BO_ 1440 brake_2: 8 XXX
 SG_ measured_lateral_acceleration : 63|1@1+ (1,0) [0|0] "" XXX
 SG_ free_brake_2_2 : 62|1@1+ (1,0) [0|0] "" XXX
 SG_ pulse_count : 56|6@1+ (1,0) [0|63] "" XXX
 SG_ fault_status_distance_pulses_4_1 : 55|1@1+ (1,0) [0|0] "" XXX
 SG_ free_brake_2_5 : 54|1@1+ (1,0) [0|0] "" XXX
 SG_ warning_lamp_DDS : 53|1@1+ (1,0) [0|0] "" XXX
 SG_ fault_memory_entry_brake : 52|1@1+ (1,0) [0|0] "" XXX
 SG_ distance_pulse_counter_status : 51|1@1+ (1,0) [0|0] "" XXX
 SG_ distance_pulses_front_axle : 40|11@1+ (1,0) [0|2047] "" XXX
 SG_ timestamp : 24|16@1+ (1,0) [0|65535] "tics" XXX
 SG_ average_wheel_rpm__brake_2 : 9|15@1+ (0.002,0) [0|65.278] "U/sec" XXX
 SG_ lateral_acceleration_TimerTic M : 8|1@1+ (1,0) [0|0] "" XXX
 SG_ Timer m1 : 0|8@1+ (0.04,0) [0|10.2] "usec" XXX
 SG_ lateral_acceleration m0 : 0|8@1+ (0.01,-1.27) [-1.27|1.27] "g" XXX

BO_ 416 brake_1: 8 ABS
 SG_ BR1_ASR_request : 0|1@1+ (1,0) [0|1] "" engine
 SG_ BR1_MSR_request M : 1|1@1+ (1,0) [0|1] "" engine
 SG_ BR1_ABS_brake : 2|1@1+ (1,0) [0|1] "" XXX
 SG_ BR1_EDS_Ongr : 3|1@1+ (1,0) [0|1] "" XXX
 SG_ BR1_ESP_Ongr : 4|1@1+ (1,0) [0|1] "" XXX
 SG_ BR1_ASR_Ongr : 5|2@1+ (1,0) [0|3] "" Transmission
 SG_ BR1_EBV_Ongr : 7|1@1+ (1,0) [0|1] "" XXX
 SG_ BR1_lamp_ABS : 8|1@1+ (1,0) [0|1] "" XXX
 SG_ BR1_lamp_ASR : 9|1@1+ (1,0) [0|1] "" XXX
 SG_ BR1_lamp_BK : 10|1@1+ (1,0) [0|1] "" XXX
 SG_ BR1_light_switch : 11|1@1+ (1,0) [0|1] "" XXX
 SG_ BR1_status_pressure_threshold : 12|1@1+ (1,0) [0|1] "" XXX
 SG_ BR1_MAD : 13|1@1+ (1,0) [0|1] "" XXX
 SG_ BR1_status_MAD : 14|1@1+ (1,0) [0|1] "" XXX
 SG_ BR1_diagnosis : 15|1@1+ (1,0) [0|1] "" XXX
 SG_ BR1_BKV_active : 16|1@1+ (1,0) [0|1] "" XXX
 SG_ BR1_wheel_kmh : 17|15@1+ (0.01,0) [0|326.39] "km/h" XXX
 SG_ BR1_ASRMo_sl : 32|8@1+ (0.39,0) [0|99.06] "%" engine
 SG_ BR1_ASRMo_fa m0 : 40|8@1+ (0.39,0) [0|99.06] "%" engine
 SG_ BR1_MSR_Mo_inv m1 : 40|8@1+ (-0.39,99.45) [0|99.06] "%" engine
 SG_ BR1_MSR_Mo : 48|8@1+ (0.39,0) [0|99.06] "%" engine
 SG_ BR1_counter : 56|4@1+ (1,0) [0|15] "" XXX
 SG_ BR1_ASR_ESP : 60|1@1+ (1,0) [0|1] "" XXX
 SG_ BR1_ESPASR_passive : 61|1@1+ (1,0) [0|1] "" XXX
 SG_ BR1_status_ESP : 62|1@1+ (1,0) [0|1] "" XXX
 SG_ BR1_replacement_Kmh : 63|1@1+ (1,0) [0|1] "" XXX

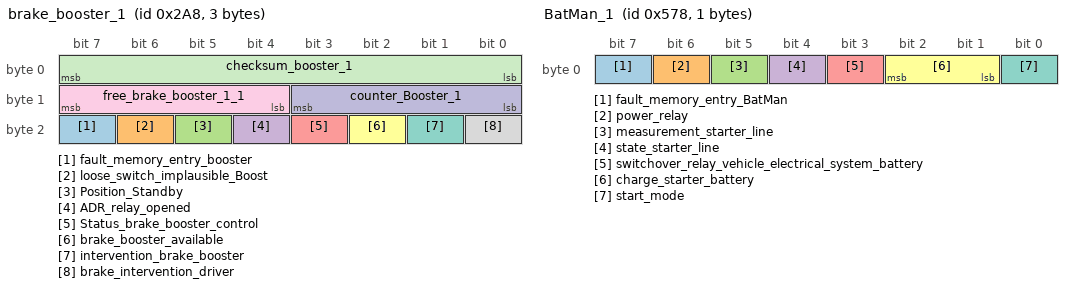
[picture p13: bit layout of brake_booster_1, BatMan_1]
BO_ 680 brake_booster_1: 3 XXX
 SG_ fault_memory_entry_booster : 23|1@1+ (1,0) [0|0] "" XXX
 SG_ loose_switch_implausible_Boost : 22|1@1+ (1,0) [0|0] "" XXX
 SG_ Position_Standby : 21|1@1+ (1,0) [0|0] "" XXX
 SG_ ADR_relay_opened : 20|1@1+ (1,0) [0|0] "" XXX
 SG_ Status_brake_booster_control : 19|1@1+ (1,0) [0|0] "" XXX
 SG_ brake_booster_available : 18|1@1+ (1,0) [0|0] "" XXX
 SG_ intervention_brake_booster : 17|1@1+ (1,0) [0|0] "" XXX
 SG_ brake_intervention_driver : 16|1@1+ (1,0) [0|0] "" XXX
 SG_ free_brake_booster_1_1 : 12|4@1+ (1,0) [0|0] "" XXX
 SG_ counter_Booster_1 : 8|4@1+ (1,0) [0|15] "" XXX
 SG_ checksum_booster_1 : 0|8@1+ (1,0) [0|0] "" XXX

BO_ 1400 BatMan_1: 1 XXX
 SG_ fault_memory_entry_BatMan : 7|1@1+ (1,0) [0|0] "" XXX
 SG_ power_relay : 6|1@1+ (1,0) [0|0] "" XXX
 SG_ measurement_starter_line : 5|1@1+ (1,0) [0|0] "" XXX
 SG_ state_starter_line : 4|1@1+ (1,0) [0|0] "" XXX
 SG_ switchover_relay_vehicle_electrical_system_battery : 3|1@1+ (1,0) [0|0] "" XXX
 SG_ charge_starter_battery : 1|2@1+ (1,0) [0|0] "" XXX
 SG_ start_mode : 0|1@1+ (1,0) [0|0] "" XXX

BO_ 704 all_wheel_drive_1: 5 XXX
 SG_ clutch_stiffness_rear_actual : 32|8@1+ (0.7874,0) [0|100] "%" XXX
 SG_ fault_memory_entry_all_wheel_drive_1 : 31|1@1+ (1,0) [0|0] "" XXX
 SG_ free_all_wheel_drive_1_1 : 26|5@1+ (1,0) [0|0] "" XXX
 SG_ shift_pre_warning : 25|1@1+ (1,0) [0|0] "" XXX
 SG_ shift_active__all_wheel_1_ : 24|1@1+ (1,0) [0|0] "" XXX
 SG_ gear_info__PNG_ : 20|4@1+ (1,0) [0|0] "" XXX
 SG_ PNG_display_blinking : 19|1@1+ (1,0) [0|0] "" XXX
 SG_ PNG_Status_4_1 : 16|3@1+ (1,0) [0|0] "" XXX
 SG_ clutch_stiffness_center_actual : 8|8@1+ (3,-381) [-381|378] "Nm/min" XXX
 SG_ unit_of_clutch_stiffness : 7|1@1+ (1,0) [0|0] "" XXX
 SG_ speed_limitation : 6|1@1+ (1,0) [0|0] "" XXX
 SG_ all_wheel_drive_warning_lamp : 5|1@1+ (1,0) [0|0] "" XXX
 SG_ limp_mode : 4|1@1+ (1,0) [0|0] "" XXX
 SG_ clutch_completely_open : 3|1@1+ (1,0) [0|0] "" XXX
 SG_ fault_status_clutch_stiffness : 2|1@1+ (1,0) [0|0] "" XXX
 SG_ overtemperature_protection_AWD_1 : 1|1@1+ (1,0) [0|0] "" XXX
 SG_ fault_all_wheel_clutch : 0|1@1+ (1,0) [0|0] "" XXX

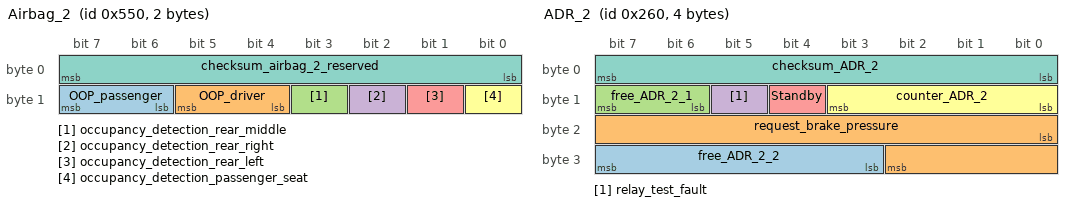
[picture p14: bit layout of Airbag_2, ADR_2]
BO_ 1360 Airbag_2: 2 XXX
 SG_ OOP_passenger : 14|2@1+ (1,0) [0|0] "" XXX
 SG_ OOP_driver : 12|2@1+ (1,0) [0|0] "" XXX
 SG_ occupancy_detection_rear_middle : 11|1@1+ (1,0) [0|0] "" XXX
 SG_ occupancy_detection_rear_right : 10|1@1+ (1,0) [0|0] "" XXX
 SG_ occupancy_detection_rear_left : 9|1@1+ (1,0) [0|0] "" XXX
 SG_ occupancy_detection_passenger_seat : 8|1@1+ (1,0) [0|0] "" XXX
 SG_ checksum_airbag_2_reserved : 0|8@1+ (1,0) [0|0] "" XXX

BO_ 80 Airbag_1: 4 XXX
 SG_ CHECKSUM : 24|8@1+ (1,0) [0|0] "" XXX
 SG_ COUNTER : 20|4@1+ (1,0) [0|15] "" XXX
 SG_ fault_memory_entry : 19|1@1+ (1,0) [0|0] "" XXX
 SG_ free_airbag_1_2 : 18|1@1+ (1,0) [0|0] "" XXX
 SG_ Airbag_in_actuator_test : 17|1@1+ (1,0) [0|0] "" XXX
 SG_ Airbag_in_diagnosis : 16|1@1+ (1,0) [0|0] "" XXX
 SG_ seatbelt_warning_passenger : 15|1@1+ (1,0) [0|0] "" XXX
 SG_ seatbelt_switch_passenger : 14|1@1+ (1,0) [0|0] "" XXX
 SG_ seatbelt_warning_driver : 13|1@1+ (1,0) [0|0] "" XXX
 SG_ seatbelt_switch_driver : 12|1@1+ (1,0) [0|0] "" XXX
 SG_ Airbag_system_fault : 11|1@1+ (1,0) [0|0] "" XXX
 SG_ child_seat_detection : 10|1@1+ (1,0) [0|0] "" XXX
 SG_ Airbag_deactivated : 9|1@1+ (1,0) [0|0] "" XXX
 SG_ Airbag_lamp : 8|1@1+ (1,0) [0|0] "" XXX
 SG_ Crash_intensity : 5|3@1+ (1,0) [0|111] "B" XXX
 SG_ Rollover : 4|1@1+ (1,0) [0|0] "" XXX
 SG_ side_crash_passenger : 3|1@1+ (1,0) [0|0] "" XXX
 SG_ side_crash_driver : 2|1@1+ (1,0) [0|0] "" XXX
 SG_ rear_Crash : 1|1@1+ (1,0) [0|0] "" XXX
 SG_ front_crash : 0|1@1+ (1,0) [0|0] "" XXX

BO_ 864 ADR_System: 8 XXX
 SG_ S_checksum_ADR_1 : 56|8@1+ (1,0) [0|0] "" XXX
 SG_ S_enable_ADR_1_1 : 52|4@1+ (1,0) [0|0] "" XXX
 SG_ S_time_gap_measured : 48|4@1+ (1,0) [0|15] "" XXX
 SG_ S_fault_memory_entry_ADR : 47|1@1+ (1,0) [0|0] "" XXX
 SG_ S_fault_memory_entry_brake_booster : 46|1@1+ (1,0) [0|0] "" XXX
 SG_ S_ADR_relay_open : 45|1@1+ (1,0) [0|0] "" XXX
 SG_ S_brake_booster_status : 43|2@1+ (1,0) [0|0] "" XXX
 SG_ S_intervention_brake_booster : 42|1@1+ (1,0) [0|0] "" XXX
 SG_ S_release_switch_implausible : 41|1@1+ (1,0) [0|0] "" XXX
 SG_ S_brake_intervention_driver : 40|1@1+ (1,0) [0|0] "" XXX
 SG_ S_display_sensor_blind : 39|1@1+ (1,0) [0|0] "" XXX
 SG_ S_control_optical_driver_warning : 38|1@1+ (1,0) [0|0] "" XXX
 SG_ S_control_gong_2 : 37|1@1+ (1,0) [0|0] "" XXX
 SG_ S_control_gong_1 : 36|1@1+ (1,0) [0|0] "" XXX
 SG_ S_shift_request : 34|2@1+ (1,0) [0|0] "" XXX
 SG_ S_display_priority : 33|1@1+ (1,0) [0|0] "" XXX
 SG_ S_display_time_gap : 32|1@1+ (1,0) [0|0] "" XXX
 SG_ S_desired_speed : 24|8@1+ (1,0) [0|254] "km/h" XXX
 SG_ S_object_detected : 22|2@1+ (1,0) [0|0] "" XXX
 SG_ S_set_time_gap__ADR_1_ : 18|4@1+ (1,0) [0|15] "" XXX
 SG_ S_synchronization_brake_booster : 17|1@1+ (1,0) [0|0] "" XXX
 SG_ S_torque_request_enable : 16|1@1+ (1,0) [0|0] "" XXX
 SG_ S_prevention_fuel_cutoff : 15|1@1+ (1,0) [0|0] "" XXX
 SG_ S_status_ADR_1__S_ : 13|2@1+ (1,0) [0|0] "" XXX
 SG_ S_fault_ADR_1__S_ : 12|1@1+ (1,0) [0|0] "" XXX
 SG_ S_counter_ADR_1 : 8|4@1+ (1,0) [0|15] "" XXX
 SG_ S_torque_request_ADR : 0|8@1+ (0.39,0) [0|99] "MDI" XXX

BO_ 608 ADR_2: 4 XXX
 SG_ free_ADR_2_2 : 27|5@1+ (1,0) [0|0] "" XXX
 SG_ request_brake_pressure : 16|11@1+ (0.0625,0) [0|127.9375] "bar" XXX
 SG_ free_ADR_2_1 : 14|2@1+ (1,0) [0|0] "" XXX
 SG_ relay_test_fault : 13|1@1+ (1,0) [0|0] "" XXX
 SG_ Standby : 12|1@1+ (1,0) [0|0] "" XXX
 SG_ counter_ADR_2 : 8|4@1+ (1,0) [0|15] "" XXX
 SG_ checksum_ADR_2 : 0|8@1+ (1,0) [0|0] "" XXX

BO_ 1324 ADR_1: 8 XXX
 SG_ checksum_ADR_1 : 56|8@1+ (1,0) [0|0] "" XXX
 SG_ free_ADR_1_5 : 52|4@1+ (1,0) [0|0] "" XXX
 SG_ time_gap_measured : 48|4@1+ (1,0) [0|15] "" XXX
 SG_ fault_memory_entry_ADR : 47|1@1+ (1,0) [0|0] "" XXX
 SG_ reserved_ADR_1_1 : 40|7@1+ (1,0) [0|0] "" XXX
 SG_ display_sensor_blind : 39|1@1+ (1,0) [0|0] "" XXX
 SG_ control_optical_driver_notice : 38|1@1+ (1,0) [0|0] "" XXX
 SG_ control_gong_2 : 37|1@1+ (1,0) [0|0] "" XXX
 SG_ control_gong_1 : 36|1@1+ (1,0) [0|0] "" XXX
 SG_ shift_request : 34|2@1+ (1,0) [0|0] "" XXX
 SG_ display_priority : 33|1@1+ (1,0) [0|0] "" XXX
 SG_ display_time_gap : 32|1@1+ (1,0) [0|0] "" XXX
 SG_ desired_speed : 24|8@1+ (1,0) [0|254] "km/h" XXX
 SG_ object_detected : 22|2@1+ (1,0) [0|0] "" XXX
 SG_ set_time_gap__ADR_1_ : 18|4@1+ (1,0) [0|15] "" XXX
 SG_ synchronization_brake_booster : 17|1@1+ (1,0) [0|0] "" XXX
 SG_ torque_request_enable : 16|1@1+ (1,0) [0|0] "" XXX
 SG_ prevention_overrun_cutoff : 15|1@1+ (1,0) [0|0] "" XXX
 SG_ Status_ADR_1 : 13|2@1+ (1,0) [0|0] "" XXX
 SG_ fault_ADR_1 : 12|1@1+ (1,0) [0|0] "" XXX
 SG_ counter_ADR_1 : 8|4@1+ (1,0) [0|15] "" XXX
 SG_ torque_request_ADR : 0|8@1+ (0.39,0) [0|99] "MDI" XXX

BO_ 1550 units_1: 2 XXX
 SG_ MFA_speed_unit_02 : 0|1@1+ (1,0) [0|1] "" XXX

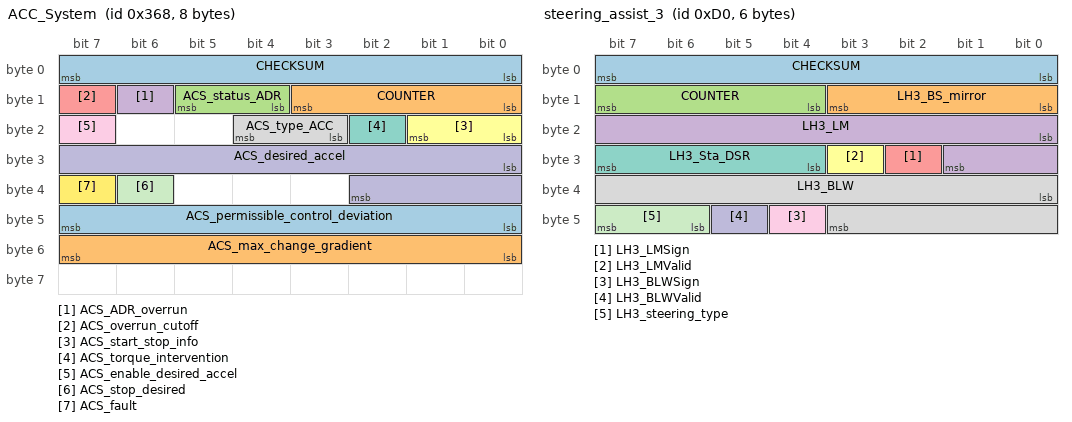
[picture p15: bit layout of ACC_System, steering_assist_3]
BO_ 872 ACC_System: 8 XXX
 SG_ CHECKSUM : 0|8@1+ (1,0) [0|255] "" XXX
 SG_ COUNTER : 8|4@1+ (1,0) [0|15] "" XXX
 SG_ ACS_status_ADR : 12|2@1+ (1,0) [0|3] "" XXX
 SG_ ACS_ADR_overrun : 14|1@1+ (1,0) [0|1] "" XXX
 SG_ ACS_overrun_cutoff : 15|1@1+ (1,0) [0|1] "" XXX
 SG_ ACS_start_stop_info : 16|2@1+ (1,0) [0|3] "" XXX
 SG_ ACS_torque_intervention : 18|1@1+ (1,0) [0|1] "" XXX
 SG_ ACS_type_ACC : 19|2@1+ (1,0) [0|3] "" XXX
 SG_ ACS_enable_desired_accel : 23|1@1+ (1,0) [0|1] "" XXX
 SG_ ACS_desired_accel : 24|11@1+ (0.005,-7.22) [-7.22|3.005] "Unit_MeterPerSeconSquar" XXX
 SG_ ACS_stop_desired : 38|1@1+ (1,0) [0|1] "" XXX
 SG_ ACS_fault : 39|1@1+ (1,0) [0|1] "" XXX
 SG_ ACS_permissible_control_deviation : 40|8@1+ (0.005,0) [0|1.265] "Unit_MeterPerSeconSquar" XXX
 SG_ ACS_max_change_gradient : 48|8@1+ (0.02,0) [0.02|5.06] "Unit_MeterPerSeconSquar" XXX

BO_ 1386 ACC_GRA_display: 8 XXX
 SG_ CHECKSUM : 0|8@1+ (1,0) [0|255] "" XXX
 SG_ ACA_status_ACC : 8|3@1+ (1,0) [0|7] "" XXX
 SG_ ACA_ID_status_ACC : 11|5@1+ (1,0) [0|31] "" XXX
 SG_ ACA_driver_hint : 16|1@1+ (1,0) [0|1] "" XXX
 SG_ ACA_display_count : 17|1@1+ (1,0) [0|1] "" XXX
 SG_ ACA_time_gap : 18|4@1+ (1,0) [0|15] "" XXX
 SG_ ACA_V_desired : 24|8@1+ (1,0) [0|255] "Unit_KiloMeterPerHour" XXX
 SG_ ACA_kmh_mph : 32|1@1+ (1,0) [0|1] "" XXX
 SG_ ACA_acoustic1 : 33|1@1+ (1,0) [0|1] "" XXX
 SG_ ACA_acoustic2 : 34|1@1+ (1,0) [0|1] "" XXX
 SG_ ACA_prio_display : 35|2@1+ (1,0) [0|3] "" XXX
 SG_ ACA_measured_time_gap : 40|4@1+ (1,0) [0|15] "" XXX
 SG_ ACA_ACC_deceleration : 44|1@1+ (1,0) [0|1] "" XXX
 SG_ ACA_status_GRA : 48|3@1+ (1,0) [0|7] "" XXX
 SG_ ACA_ID_status_GRA : 51|5@1+ (1,0) [0|31] "" XXX
 SG_ ACA_coding : 56|1@1+ (1,0) [0|1] "" XXX
 SG_ ACA_speedo_ring : 57|1@1+ (1,0) [0|1] "" XXX
 SG_ ACA_change_time_gap : 58|1@1+ (1,0) [0|1] "" XXX
 SG_ COUNTER : 60|4@1+ (1,0) [0|15] "" XXX

BO_ 208 steering_assist_3: 6 XXX
 SG_ CHECKSUM : 0|8@1+ (1,0) [0|255] "" XXX
 SG_ LH3_BS_mirror : 8|4@1+ (1,0) [0|15] "" XXX
 SG_ COUNTER : 12|4@1+ (1,0) [0|15] "" XXX
 SG_ LH3_LM : 16|10@1+ (1,0) [0|1023] "" XXX
 SG_ LH3_LMSign : 26|1@1+ (1,0) [0|1] "" XXX
 SG_ LH3_LMValid : 27|1@1+ (1,0) [0|1] "" XXX
 SG_ LH3_Sta_DSR : 28|4@1+ (1,0) [0|15] "" XXX
 SG_ LH3_BLW : 32|12@1+ (0.15,0) [0|615] "" XXX
 SG_ LH3_BLWSign : 44|1@1+ (1,0) [0|1] "" XXX
 SG_ LH3_BLWValid : 45|1@1+ (1,0) [0|1] "" XXX
 SG_ LH3_steering_type : 46|2@1+ (1,0) [0|3] "" XXX

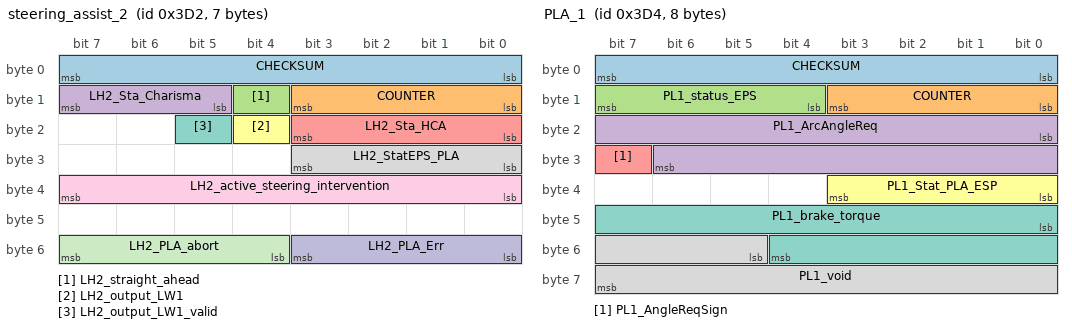
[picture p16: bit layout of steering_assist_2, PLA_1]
BO_ 978 steering_assist_2: 7 XXX
 SG_ CHECKSUM : 0|8@1+ (1,0) [0|255] "" XXX
 SG_ COUNTER : 8|4@1+ (1,0) [0|15] "" XXX
 SG_ LH2_straight_ahead : 12|1@1+ (1,0) [0|1] "" XXX
 SG_ LH2_Sta_Charisma : 13|3@1+ (1,0) [0|7] "" XXX
 SG_ LH2_Sta_HCA : 16|4@1+ (1,0) [0|15] "" XXX
 SG_ LH2_output_LW1 : 20|1@1+ (1,0) [0|1] "" XXX
 SG_ LH2_output_LW1_valid : 21|1@1+ (1,0) [0|1] "" XXX
 SG_ LH2_StatEPS_PLA : 24|4@1+ (1,0) [0|15] "" XXX
 SG_ LH2_active_steering_intervention : 32|8@1+ (1,0) [0|255] "" XXX
 SG_ LH2_PLA_Err : 48|4@1+ (1,0) [0|15] "" XXX
 SG_ LH2_PLA_abort : 52|4@1+ (1,0) [0|15] "" XXX

BO_ 980 PLA_1: 8 XXX
 SG_ CHECKSUM : 0|8@1+ (1,0) [0|255] "" XXX
 SG_ COUNTER : 8|4@1+ (1,0) [0|15] "" XXX
 SG_ PL1_status_EPS : 12|4@1+ (1,0) [0|15] "" XXX
 SG_ PL1_ArcAngleReq : 16|15@1+ (0.04375,0) [0|1433.55625] "Unit_DegreeOfArc" XXX
 SG_ PL1_AngleReqSign : 31|1@1+ (1,0) [0|1] "" XXX
 SG_ PL1_Stat_PLA_ESP : 32|4@1+ (1,0) [0|10] "" Vector__XXX
 SG_ PL1_brake_torque : 40|13@1+ (4,0) [0|32760] "Unit_NewtoMeter" Vector__XXX
 SG_ PL1_void : 53|11@1+ (1,0) [0|2047] "" XXX

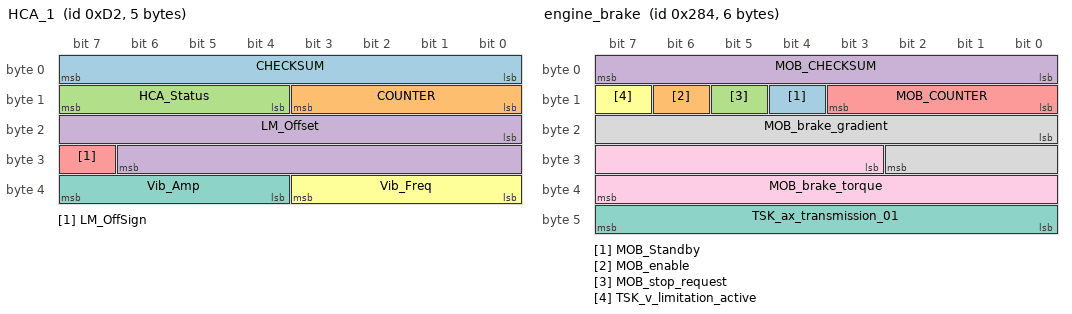
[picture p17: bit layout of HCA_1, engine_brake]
BO_ 210 HCA_1: 5 XXX
 SG_ CHECKSUM : 0|8@1+ (1,0) [0|15] "" XXX
 SG_ COUNTER : 8|4@1+ (1,0) [0|15] "" XXX
 SG_ HCA_Status : 12|4@1+ (1,0) [0|15] "" XXX
 SG_ LM_Offset : 16|15@1+ (0.03125,0) [0|300] "cNm" XXX
 SG_ LM_OffSign : 31|1@1+ (1,0) [0|1] "" XXX
 SG_ Vib_Freq : 32|4@1+ (4,0) [0|60] "Hz" XXX
 SG_ Vib_Amp : 36|4@1+ (0.5,0) [0|7.5] "Nm" XXX

BO_ 644 engine_brake: 6 XXX
 SG_ MOB_Standby : 12|1@1+ (1,0) [0|1] ""  XXX
 SG_ MOB_enable : 14|1@1+ (1,0) [0|1] "" BCM_Gateway,brake_MK25AESP,Gateway_separat
 SG_ MOB_stop_request : 13|1@1+ (1,0) [0|1] "" brake_MK25AESP,transmission_DQ
 SG_ MOB_CHECKSUM : 0|8@1+ (1,0) [0|255] "" brake_MK25AESP
 SG_ MOB_COUNTER : 8|4@1+ (1,0) [0|15] "" brake_MK25AESP
 SG_ TSK_v_limitation_active : 15|1@0+ (1,0) [0|1] "" XXX
 SG_ TSK_ax_transmission_01 : 40|8@1+ (0.048,0) [0|255] "m/s2" XXX
 SG_ MOB_brake_gradient : 16|11@1+ (0.048852,0) [0|100] "Unit_PerCent" Vector__XXX
 SG_ MOB_brake_torque : 27|13@1+ (4,0) [0|32760] "Unit_NewtoMeter"  brake_MK25AESP

BO_ 870 AWV: 8 XXX
 SG_ CHECKSUM : 0|8@1+ (1,0) [0|255] "" Vector__XXX
 SG_ COUNTER : 8|4@1+ (1,0) [0|15] "" Vector__XXX
 SG_ AWV_text : 12|4@1+ (1,0) [0|14] "" Vector__XXX
 SG_ AWV_1_enable : 16|1@1+ (1,0) [0|1] "" Vector__XXX
 SG_ AWV_1_Prefill : 17|1@1+ (1,0) [0|1] "" Vector__XXX
 SG_ AWV_1_parameter : 18|2@1+ (1,0) [0|3] "" Vector__XXX
 SG_ AWV_only : 20|1@1+ (1,0) [0|1] "" Vector__XXX
 SG_ AWV_CityANB_variant : 21|1@1+ (1,0) [0|1] "" Vector__XXX
 SG_ AWV_hold : 22|1@1+ (1,0) [0|1] "" Vector__XXX
 SG_ ANB_partial_braking_enable : 23|1@1+ (1,0) [0|1] "" Vector__XXX
 SG_ AWV_2_status : 24|1@1+ (1,0) [0|1] "" Vector__XXX
 SG_ AWV_2_fault : 25|1@1+ (1,0) [0|1] "" Vector__XXX
 SG_ AWV_2_SU_warning_time : 26|2@1+ (1,0) [0|3] "" Vector__XXX
 SG_ AWV_2_SU_brake_jerk : 28|1@1+ (1,0) [0|1] "" Vector__XXX
 SG_ AWV_2_SU_gong : 29|1@1+ (1,0) [0|1] "" Vector__XXX
 SG_ AWV_2_SU_lamp : 30|1@1+ (1,0) [0|1] "" Vector__XXX
 SG_ AWV_2_surroundings_warning : 31|1@1+ (1,0) [0|1] "" Vector__XXX
 SG_ AWV_2_enable : 32|1@1+ (1,0) [0|1] "" Vector__XXX
 SG_ AWV_2_jerk_profile : 33|3@1+ (1,0) [0|7] "" Vector__XXX
 SG_ AWV_2_warning_tone : 36|1@1+ (1,0) [0|1] "" Vector__XXX
 SG_ AWV_2_warning_symbol : 37|1@1+ (1,0) [0|1] "" Vector__XXX
 SG_ AWV_info_tone : 38|1@1+ (1,0) [0|1] "" Vector__XXX
 SG_ AWV_2_belt_tensioner : 39|1@1+ (1,0) [0|1] "" Vector__XXX
 SG_ AWV_configuration_menu_request : 40|1@1+ (1,0) [0|1] "" Vector__XXX
 SG_ AWV_configuration_forward_menu_request : 41|1@1+ (1,0) [0|1] "" Vector__XXX
 SG_ AWV_configuration_status : 42|1@1+ (1,0) [0|1] "" Vector__XXX
 SG_ AWV_configuration_forward_status : 43|1@1+ (1,0) [0|1] "" Vector__XXX
 SG_ AWV_2_distance_warning : 51|1@1+ (1,0) [0|1] "" Vector__XXX
 SG_ ANB_target_braking_enable : 52|1@1+ (1,0) [0|1] "" Vector__XXX
 SG_ ANB_CM_request : 53|1@1+ (1,0) [0|1] "" Vector__XXX
 SG_ ANB_target_partial_brake_deceleration_request : 54|10@1+ (0.024,-20.016) [0|1023] "Unit_MeterPerSeconSquar" Vector__XXX

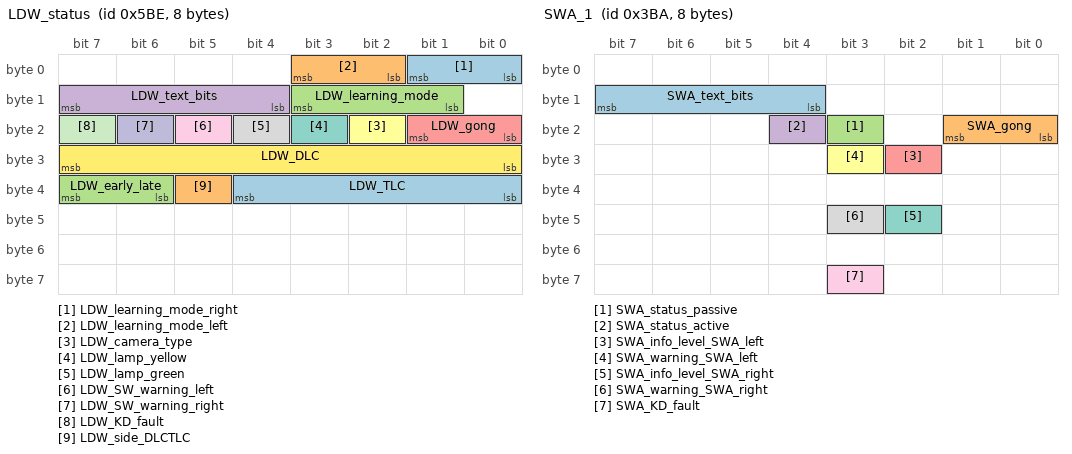
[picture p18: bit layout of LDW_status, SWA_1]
BO_ 1470 LDW_status: 8 XXX
 SG_ LDW_learning_mode_right : 0|2@1+ (1,0) [0|3] "" XXX
 SG_ LDW_learning_mode_left : 2|2@1+ (1,0) [0|3] "" XXX
 SG_ LDW_learning_mode : 9|3@1+ (1,0) [0|3] "" XXX
 SG_ LDW_text_bits : 12|4@1+ (1,0) [0|15] "" XXX
 SG_ LDW_gong : 16|2@1+ (1,0) [0|3] "" XXX
 SG_ LDW_camera_type : 18|1@1+ (1,0) [0|1] "" XXX
 SG_ LDW_lamp_yellow : 19|1@1+ (1,0) [0|1] "" XXX
 SG_ LDW_lamp_green : 20|1@1+ (1,0) [0|1] "" XXX
 SG_ LDW_SW_warning_left : 21|1@1+ (1,0) [0|1] "" XXX
 SG_ LDW_SW_warning_right : 22|1@1+ (1,0) [0|1] "" XXX
 SG_ LDW_KD_fault : 23|1@1+ (1,0) [0|1] "" XXX
 SG_ LDW_DLC : 24|8@1+ (0.01,-1.25) [-1.25|1.25] "" XXX
 SG_ LDW_TLC : 32|5@1+ (0.1,0) [0|3] "" XXX
 SG_ LDW_side_DLCTLC : 37|1@1+ (1,0) [0|1] "" XXX
 SG_ LDW_early_late : 38|2@1+ (1,0) [0|3] "" XXX

BO_ 428 brake_8: 8 XXX
 SG_ BR8_checksum : 0|8@1+ (1,0) [0|255] "" XXX
 SG_ BR8_counter : 8|4@1+ (1,0) [0|15] "" XXX
 SG_ BR8_status_ACC_request : 12|1@1+ (1,0) [0|1] "" XXX
 SG_ BR8_deceleration_EPB_active : 13|1@1+ (1,0) [0|1] "" XXX
 SG_ BR8_status_brake_temp : 14|1@1+ (1,0) [0|1] "" XXX
 SG_ BR8_status_brake_pressure : 15|1@1+ (1,0) [0|1] "" XXX
 SG_ BR8_tolerance_adjustment_HL : 16|8@1+ (0.048828125,-6.201171875) [-6.201171875|6.15234375] "Unit_PerCent" XXX
 SG_ BR8_tolerance_adjustment_HR : 24|8@1+ (0.048828125,-6.201171875) [-6.201171875|6.15234375] "Unit_PerCent" XXX
 SG_ BR8_actual_acceleration : 32|9@1+ (0.02,-7.22) [-7.22|2.98] "Unit_MeterPerSeconSquar"  XXX
 SG_ BR8_status_HW_BLS : 41|1@1+ (1,0) [0|1] "" XXX
 SG_ BR8_QB_longitudinal_acceleration : 42|1@1+ (1,0) [0|1] "" XXX
 SG_ BR8_ESC_Mode : 43|2@1+ (1,0) [0|3] "" XXX
 SG_ BR8_active_brake_system : 45|1@1+ (1,0) [0|1] "" XXX
 SG_ BR8_driver_braking : 46|1@1+ (1,0) [0|1] "" XXX
 SG_ BR8_status_brake_system : 47|1@1+ (1,0) [0|1] "" XXX
 SG_ BR8_longitudinal_acceleration : 48|10@1+ (0.03125,-16) [-15.96875|15.9375] "Unit_MeterPerSeconSquar" XXX
 SG_ BR8_status_ADR_brake : 58|1@1+ (1,0) [0|1] "" XXX
 SG_ BR8_Quattro : 59|1@1+ (1,0) [0|1] "" XXX
 SG_ BR8_status_deceleration_control : 60|1@1+ (1,0) [0|1] "" XXX
 SG_ BR8_status_BLS : 61|1@1+ (1,0) [0|1] "" XXX
 SG_ BR8_deceleration_EPB : 62|1@1+ (1,0) [0|1] "" XXX
 SG_ BR8_Check_EPB : 63|1@1+ (1,0) [0|1] "" XXX

BO_ 928 brake_10: 8 XXX
 SG_ B10_checksum : 0|8@1+ (1,0) [0|255] "" XXX
 SG_ B10_counter : 8|4@1+ (1,0) [0|15] "" XXX
 SG_ B10_QB_distance_pulses_VL : 12|1@1+ (1,0) [0|1] "" XXX
 SG_ B10_QB_distance_pulses_VR : 13|1@1+ (1,0) [0|1] "" XXX
 SG_ B10_QB_distance_pulses_HL : 14|1@1+ (1,0) [0|1] "" XXX
 SG_ B10_QB_distance_pulses_HR : 15|1@1+ (1,0) [0|1] "" XXX
 SG_ B10_distance_pulses_VL : 16|10@1+ (1,0) [0|1000] "" XXX
 SG_ B10_distance_pulses_VR : 26|10@1+ (1,0) [0|1000] "" XXX
 SG_ B10_distance_pulses_HL : 36|10@1+ (1,0) [0|1000] "" XXX
 SG_ B10_distance_pulses_HR : 46|10@1+ (1,0) [0|1000] "" XXX
 SG_ B10_QB_direction_VL : 56|1@1+ (1,0) [0|1] "" XXX
 SG_ B10_QB_direction_VR : 57|1@1+ (1,0) [0|1] "" XXX
 SG_ B10_QB_direction_HL : 58|1@1+ (1,0) [0|1] "" XXX
 SG_ B10_QB_direction_HR : 59|1@1+ (1,0) [0|1] "" XXX
 SG_ B10_direction_VL : 60|1@1+ (1,0) [0|1] "" XXX
 SG_ B10_direction_VR : 61|1@1+ (1,0) [0|1] "" XXX
 SG_ B10_direction_HL : 62|1@1+ (1,0) [0|1] "" XXX
 SG_ B10_direction_HR : 63|1@1+ (1,0) [0|1] "" XXX

BO_ 835 RDK_status: 3 XXX
 SG_ RKS_tire_VL : 0|1@1+ (1,0) [0|1] "" XXX
 SG_ RKS_tire_VR : 1|1@1+ (1,0) [0|1] "" XXX
 SG_ RKS_tire_HL : 2|1@1+ (1,0) [0|1] "" XXX
 SG_ RKS_tire_HR : 3|1@1+ (1,0) [0|1] "" XXX
 SG_ RKS_tire_RR : 4|1@1+ (1,0) [0|1] "" XXX
 SG_ RKS_warning_2 : 5|1@1+ (1,0) [0|1] "" XXX
 SG_ RKS_warning_1 : 6|1@1+ (1,0) [0|1] "" XXX
 SG_ RKS_system_fault : 7|1@1+ (1,0) [0|1] "" XXX
 SG_ RKS_calibration_rejected : 8|1@1+ (1,0) [0|1] "" XXX
 SG_ RKS_pressure_diff_front : 9|1@1+ (1,0) [0|1] "" XXX
 SG_ RKS_pressure_diff_rear : 10|1@1+ (1,0) [0|1] "" XXX
 SG_ RKS_filling_RR_low : 11|1@1+ (1,0) [0|1] "" XXX
 SG_ RKS_radio_interference : 12|1@1+ (1,0) [0|1] "" XXX
 SG_ RKS_system_off : 13|1@1+ (1,0) [0|1] "" XXX
 SG_ RKS_KD_fault : 15|1@1+ (1,0) [0|1] "" XXX
 SG_ RKS_lamp : 16|1@1+ (1,0) [0|1] "" XXX
 SG_ RKS_tone : 17|1@1+ (1,0) [0|1] "" XXX
 SG_ RKS_gong : 18|1@1+ (1,0) [0|1] "" XXX
 SG_ RKS_RDK_blink_bit : 19|1@1+ (1,0) [0|1] "" XXX
 SG_ RKS_partial_load : 20|1@1+ (1,0) [0|1] "" XXX

BO_ 914 Gate_Komf_2: 8 XXX
 SG_ GK2_Sta_LSM : 0|1@1+ (1,0) [0|1] "" XXX
 SG_ GK2_Sta_light_sensor : 1|1@1+ (1,0) [0|1] "" XXX
 SG_ GK2_Sta_light1 : 2|1@1+ (1,0) [0|1] "" XXX
 SG_ GK2_Sta_VSG : 3|1@1+ (1,0) [0|1] "" XXX
 SG_ GK2_Sta_key : 4|1@1+ (1,0) [0|1] "" XXX
 SG_ GK2_Sta_profile : 5|1@1+ (1,0) [0|1] "" XXX
 SG_ GK2_Sta_Clima2 : 6|1@1+ (1,0) [0|1] "" XXX
 SG_ GK2_Sta_BSG4 : 7|1@1+ (1,0) [0|1] "" XXX
 SG_ GK2_Sta_Kessy_4 : 8|1@1+ (1,0) [0|1] "" XXX
 SG_ BS4_sliding_headlight_range_request : 9|1@1+ (1,0) [0|1] "" XXX
 SG_ BS4_GLW_high_beam_request : 10|1@1+ (1,0) [0|1] "" XXX
 SG_ GK2_Blk_L_control : 11|1@1+ (1,0) [0|1] "" XXX
 SG_ GK2_Blk_R_control : 12|1@1+ (1,0) [0|1] "" XXX
 SG_ GK2_LS_Kom_error : 14|1@1+ (1,0) [0|1] "" XXX
 SG_ GK2_LS_def : 15|1@1+ (1,0) [0|1] "" XXX
 SG_ GK2_brightness : 16|3@1+ (714.286,0) [0|5000.002] "Unit_Lux" XXX
 SG_ GK2_VD_closed_ver : 19|1@1+ (1,0) [0|1] "" XXX
 SG_ GK2_VD_unlocked : 20|1@1+ (1,0) [0|1] "" XXX
 SG_ GK2_VD_open_ver : 21|1@1+ (1,0) [0|1] "" XXX
 SG_ GK2_convertible_top_Anf : 22|1@1+ (1,0) [0|1] "" XXX
 SG_ GK2_VDKD_open : 23|1@1+ (1,0) [0|1] "" XXX
 SG_ GK2_key : 24|4@1+ (1,0) [0|15] "" XXX
 SG_ GK2_Hardtop : 28|1@1+ (1,0) [0|1] "" XXX
 SG_ GK2_AFL_switch : 29|1@1+ (1,0) [0|1] "" XXX
 SG_ GK2_rear_fog : 30|1@1+ (1,0) [0|1] "" XXX
 SG_ GK2_EM_LIN_invalid : 31|1@1+ (1,0) [0|1] "" XXX
 SG_ GK2_profile : 32|4@1+ (1,0) [0|15] "" XXX
 SG_ GK2_Kl_StSt_Info : 36|2@1+ (1,0) [0|3] "" XXX
 SG_ GK2_BSG_StSt_info : 38|2@1+ (1,0) [0|3] "" XXX
 SG_ GK2_BEM_P_generator : 40|8@1+ (50,0) [0|12700] "Unit_Watt" XXX
 SG_ GK2_BEM_shutdown_stages : 48|3@1+ (1,0) [0|7] "" XXX
 SG_ GK2_BEM_DFM : 51|5@1+ (3.225,0.025) [0.025|100] "Unit_PerCent" XXX
 SG_ GK2_Kessy_StSt_Info : 56|2@1+ (1,0) [0|3] "" XXX
 SG_ GK2_BEM_StSt_info : 58|2@1+ (1,0) [0|3] "" XXX

BO_ 954 SWA_1: 8 SWA
 SG_ SWA_text_bits : 12|4@1+ (1,0) [0|15] ""  XXX
 SG_ SWA_gong : 16|2@1+ (1,0) [0|3] ""  XXX
 SG_ SWA_status_passive : 19|1@1+ (1,0) [0|1] ""  XXX
 SG_ SWA_status_active : 20|1@1+ (1,0) [0|1] ""  XXX
 SG_ SWA_info_level_SWA_left : 26|1@1+ (1,0) [0|1] ""  XXX
 SG_ SWA_warning_SWA_left : 27|1@1+ (1,0) [0|1] ""  XXX
 SG_ SWA_info_level_SWA_right : 42|1@1+ (1,0) [0|1] ""  XXX
 SG_ SWA_warning_SWA_right : 43|1@1+ (1,0) [0|1] ""  XXX
 SG_ SWA_KD_fault : 59|1@1+ (1,0) [0|1] ""  XXX

BO_ 1175 park_assist_01: 8 XXX
 SG_ PH_shutdown_cause : 13|3@1+ (1,0) [0|7] "" XXX
 SG_ PH_Opt_display_V_on : 16|1@1+ (1,0) [0|1] "" XXX
 SG_ PH_Opt_display_H_on : 17|1@1+ (1,0) [0|1] "" XXX
 SG_ PH_Opt_display_V_obstacle : 18|1@1+ (1,0) [0|1] "" XXX
 SG_ PH_Opt_display_H_obstacle : 19|1@1+ (1,0) [0|1] "" XXX
 SG_ PH_buzzer_V_active : 20|1@1+ (1,0) [0|1] "" XXX
 SG_ PH_buzzer_H_active : 21|1@1+ (1,0) [0|1] "" XXX
 SG_ PH_buzzer_mute : 22|1@1+ (1,0) [0|1] "" XXX
 SG_ PH_request_audio_reduction : 23|1@1+ (1,0) [0|1] "" XXX
 SG_ PH_frequency_rear : 32|4@1+ (1,0) [0|15] "" XXX
 SG_ PH_volume_rear : 36|4@1+ (1,0) [0|15] "" XXX
 SG_ PH_frequency_front : 40|4@1+ (1,0) [0|15] "" XXX
 SG_ PH_volume_front : 44|4@1+ (1,0) [0|15] "" XXX
 SG_ PH_trigger_image_activation : 48|1@1+ (1,0) [0|1] "" XXX
 SG_ PH_start_stop_Info : 49|2@1+ (1,0) [0|3] "" XXX
 SG_ PH_attachments_detected : 51|1@1+ (1,0) [0|1] "" XXX
 SG_ PH_area_detection_front : 52|2@1+ (1,0) [0|3] "" XXX
 SG_ PH_area_detection_rear : 54|2@1+ (1,0) [0|3] "" XXX
 SG_ PH_defective : 56|1@1+ (1,0) [0|1] "" XXX
 SG_ PH_disturbed : 57|1@1+ (1,0) [0|1] "" XXX
 SG_ PH_system_state : 58|3@1+ (1,0) [0|7] "" XXX
 SG_ PH_display_customer_request : 61|2@1+ (1,0) [0|3] "" XXX
 SG_ PH_KD_fault : 63|1@1+ (1,0) [0|1] "" XXX

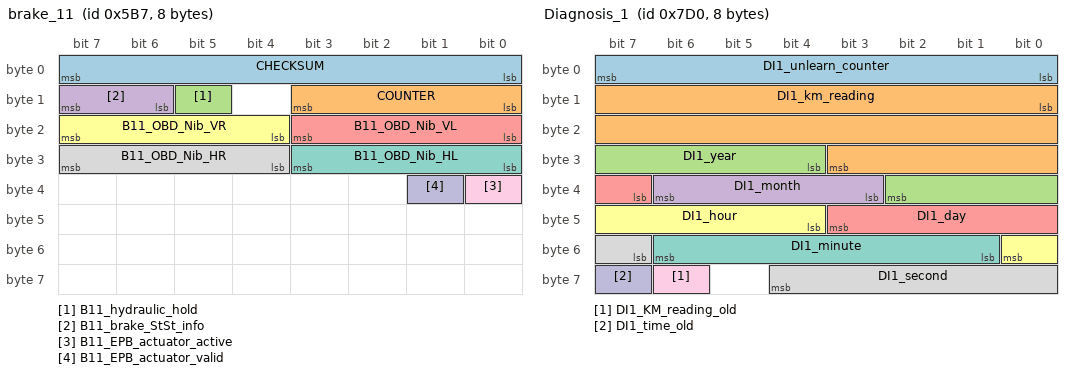
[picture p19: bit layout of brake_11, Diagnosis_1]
BO_ 1463 brake_11: 8 XXX
 SG_ CHECKSUM : 0|8@1+ (1,0) [0|255] "" XXX
 SG_ COUNTER : 8|4@1+ (1,0) [0|15] "" XXX
 SG_ B11_hydraulic_hold : 13|1@1+ (1,0) [0|1] "" XXX
 SG_ B11_brake_StSt_info : 14|2@1+ (1,0) [0|3] "" XXX
 SG_ B11_OBD_Nib_VL : 16|4@1+ (1,0) [0|15] "" XXX
 SG_ B11_OBD_Nib_VR : 20|4@1+ (1,0) [0|15] "" XXX
 SG_ B11_OBD_Nib_HL : 24|4@1+ (1,0) [0|15] "" XXX
 SG_ B11_OBD_Nib_HR : 28|4@1+ (1,0) [0|15] "" XXX
 SG_ B11_EPB_actuator_active : 32|1@1+ (1,0) [0|1] "" XXX
 SG_ B11_EPB_actuator_valid : 33|1@1+ (1,0) [0|1] "" XXX

BO_ 1500 target_installation_list_new: 8 XXX
 SG_ VL1_engine_SG : 0|1@1+ (1,0) [0|1] "" XXX
 SG_ VL1_transmission_SG : 1|1@1+ (1,0) [0|1] "" XXX
 SG_ VL1_ABS : 2|1@1+ (1,0) [0|1] "" XXX
 SG_ VL1_cluster : 3|1@1+ (1,0) [0|1] "" XXX
 SG_ VL1_LSM : 4|1@1+ (1,0) [0|1] "" XXX
 SG_ VL1_airbag : 5|1@1+ (1,0) [0|1] "" XXX
 SG_ VL1_steering_assist : 6|1@1+ (1,0) [0|1] "" XXX
 SG_ VL1_dyn_LWR : 7|1@1+ (1,0) [0|1] "" XXX
 SG_ VL1_res_08 : 8|1@1+ (1,0) [0|1] "" XXX
 SG_ VL1_all_wheel_drive : 9|1@1+ (1,0) [0|1] "" XXX
 SG_ VL1_ADR : 10|1@1+ (1,0) [0|1] "" XXX
 SG_ VL1_ADR_separated : 11|1@1+ (1,0) [0|1] "" XXX
 SG_ VL1_EPB : 12|1@1+ (1,0) [0|1] "" XXX
 SG_ VL1_res_13 : 13|1@1+ (1,0) [0|1] "" XXX
 SG_ VL1_damper : 14|1@1+ (1,0) [0|1] "" XXX
 SG_ VL1_cross_lock : 15|1@1+ (1,0) [0|1] "" XXX
 SG_ VL1_engine_slave : 16|1@1+ (1,0) [0|1] "" XXX
 SG_ VL1_SWA : 17|1@1+ (1,0) [0|1] "" XXX
 SG_ VL1_HCA : 18|1@1+ (1,0) [0|1] "" XXX
 SG_ VL1_RKA_Plus : 19|1@1+ (1,0) [0|1] "" XXX
 SG_ VL1_PLA : 20|1@1+ (1,0) [0|1] "" XXX
 SG_ VL1_WFS_KBI : 21|1@1+ (1,0) [0|1] "" XXX
 SG_ VL1_cluster_KBI : 22|1@1+ (1,0) [0|1] "" XXX
 SG_ VL1_target_eq_actual : 23|1@1+ (1,0) [0|1] "" XXX
 SG_ VL1_BSG_comfort : 24|1@1+ (1,0) [0|1] "" XXX
 SG_ VL1_ZKE : 25|1@1+ (1,0) [0|1] "" XXX
 SG_ VL1_TSG_FT : 26|1@1+ (1,0) [0|1] "" XXX
 SG_ VL1_TSG_BT : 27|1@1+ (1,0) [0|1] "" XXX
 SG_ VL1_TSG_HL : 28|1@1+ (1,0) [0|1] "" XXX
 SG_ VL1_TSG_HR : 29|1@1+ (1,0) [0|1] "" XXX
 SG_ VL1_memory : 30|1@1+ (1,0) [0|1] "" XXX
 SG_ VL1_roof_module_K : 31|1@1+ (1,0) [0|1] "" XXX
 SG_ VL1_central_electrics_II : 32|1@1+ (1,0) [0|1] "" XXX
 SG_ VL1_RDK : 33|1@1+ (1,0) [0|1] "" XXX
 SG_ VL1_steering_column : 34|1@1+ (1,0) [0|1] "" XXX
 SG_ VL1_gateway : 35|1@1+ (1,0) [0|1] "" XXX
 SG_ VL1_clima_comfort : 36|1@1+ (1,0) [0|1] "" XXX
 SG_ VL1_park_assist : 37|1@1+ (1,0) [0|1] "" XXX
 SG_ VL1_PTC_heater : 38|1@1+ (1,0) [0|1] "" XXX
 SG_ VL1_parking_heater : 39|1@1+ (1,0) [0|1] "" XXX
 SG_ VL1_convertible_top : 40|1@1+ (1,0) [0|1] "" XXX
 SG_ VL1_RSE_I : 41|1@1+ (1,0) [0|1] "" XXX
 SG_ VL1_res_42 : 42|1@1+ (1,0) [0|1] "" XXX
 SG_ VL1_MDI_I : 43|1@1+ (1,0) [0|1] "" XXX
 SG_ VL1_trailer : 44|1@1+ (1,0) [0|1] ""  SWA
 SG_ VL1_memory_BF : 45|1@1+ (1,0) [0|1] "" XXX
 SG_ VL1_Easy_Entry_VF : 46|1@1+ (1,0) [0|1] "" XXX
 SG_ VL1_Easy_Entry_VB : 47|1@1+ (1,0) [0|1] "" XXX
 SG_ VL1_tailgate : 48|1@1+ (1,0) [0|1] "" XXX
 SG_ VL1_Rearview : 49|1@1+ (1,0) [0|1] "" XXX
 SG_ VL1_special_vehicle_SG : 50|1@1+ (1,0) [0|1] "" XXX
 SG_ VL1_button_module : 51|1@1+ (1,0) [0|1] "" XXX
 SG_ VL1_compass : 52|1@1+ (1,0) [0|1] "" XXX
 SG_ VL1_WFS_K : 53|1@1+ (1,0) [0|1] "" XXX
 SG_ VL1_GSM_pager : 54|1@1+ (1,0) [0|1] "" XXX
 SG_ VL1_info_electronics : 55|1@1+ (1,0) [0|1] "" XXX
 SG_ VL1_DSP : 56|1@1+ (1,0) [0|1] "" XXX
 SG_ VL1_DAB : 57|1@1+ (1,0) [0|1] "" XXX
 SG_ VL1_telematics : 58|1@1+ (1,0) [0|1] "" XXX
 SG_ VL1_navigation : 59|1@1+ (1,0) [0|1] "" XXX
 SG_ VL1_TV_tuner : 60|1@1+ (1,0) [0|1] "" XXX
 SG_ VL1_tilt_module_I : 61|1@1+ (1,0) [0|1] "" XXX
 SG_ VL1_Radio : 62|1@1+ (1,0) [0|1] "" XXX
 SG_ VL1_telephone : 63|1@1+ (1,0) [0|1] "" XXX

BO_ 1490 Ident: 8 XXX
 SG_ IDT_Mux M : 0|2@1+ (1,0) [0|2] "" XXX
 SG_ IDT_secret_1 m0 : 8|8@1+ (1,0) [0|255] "" XXX
 SG_ IDT_VIN_4 m1 : 8|8@1+ (1,0) [0|255] "" XXX
 SG_ IDT_VIN_11 m2 : 8|8@1+ (1,0) [0|255] "" XXX
 SG_ IDT_secret_2 m0 : 16|8@1+ (1,0) [0|255] "" XXX
 SG_ IDT_VIN_5 m1 : 16|8@1+ (1,0) [0|255] "" XXX
 SG_ IDT_VIN_12 m2 : 16|8@1+ (1,0) [0|255] "" XXX
 SG_ IDT_secret_3 m0 : 24|8@1+ (1,0) [0|255] "" XXX
 SG_ IDT_VIN_6 m1 : 24|8@1+ (1,0) [0|255] "" XXX
 SG_ IDT_VIN_13 m2 : 24|8@1+ (1,0) [0|255] "" XXX
 SG_ IDT_secret_4 m0 : 32|8@1+ (1,0) [0|255] "" XXX
 SG_ IDT_VIN_7 m1 : 32|8@1+ (1,0) [0|255] "" XXX
 SG_ IDT_VIN_14 m2 : 32|8@1+ (1,0) [0|255] "" XXX
 SG_ IDT_VIN_1 m0 : 40|8@1+ (1,0) [0|255] "" XXX
 SG_ IDT_VIN_8 m1 : 40|8@1+ (1,0) [0|255] "" XXX
 SG_ IDT_VIN_15 m2 : 40|8@1+ (1,0) [0|255] "" XXX
 SG_ IDT_VIN_2 m0 : 48|8@1+ (1,0) [0|255] "" XXX
 SG_ IDT_VIN_9 m1 : 48|8@1+ (1,0) [0|255] "" XXX
 SG_ IDT_VIN_16 m2 : 48|8@1+ (1,0) [0|255] "" XXX
 SG_ IDT_VIN_3 m0 : 56|8@1+ (1,0) [0|255] "" XXX
 SG_ IDT_VIN_10 m1 : 56|8@1+ (1,0) [0|255] "" XXX
 SG_ IDT_VIN_17 m2 : 56|8@1+ (1,0) [0|255] "" XXX

BO_ 2000 Diagnosis_1: 8 XXX
 SG_ DI1_unlearn_counter : 0|8@1+ (1,0) [0|254] "" XXX
 SG_ DI1_km_reading : 8|20@1+ (1,0) [0|1048575] "Unit_KiloMeter" XXX
 SG_ DI1_year : 28|7@1+ (1,2000) [2000|2127] "Unit_Year" XXX
 SG_ DI1_month : 35|4@1+ (1,0) [1|12] "Unit_Month" XXX
 SG_ DI1_day : 39|5@1+ (1,0) [0|31] "Unit_Day" XXX
 SG_ DI1_hour : 44|5@1+ (1,0) [0|23] "Unit_Hours" XXX
 SG_ DI1_minute : 49|6@1+ (1,0) [0|59] "Unit_Minut" XXX
 SG_ DI1_second : 55|6@1+ (1,0) [0|59] "Unit_Secon" XXX
 SG_ DI1_KM_reading_old : 62|1@1+ (1,0) [0|1] "" XXX
 SG_ DI1_time_old : 63|1@1+ (1,0) [0|1] "" XXX

CM_ SG_ 80 checksum_airbag_1 "Checksum Airbag_1";
CM_ SG_ 80 counter_Airbag_1 "Counter Airbag_1";

CM_ BO_ 194 "Steering wheel angle message 1 - Contains steering angle, speed, and status information";

CM_ SG_ 194 LW1_LRW "Steering wheel angle (0 = straight ahead, 7FFFh = stop)";
CM_ SG_ 194 LW1_LRW_sign "Steering angle sign: 0=positive (left), 1=negative (right)";
CM_ SG_ 194 LW1_steering_speed "Steering wheel angular velocity (0 = no movement, 7FFFh = max speed)";
CM_ SG_ 194 LW1_speed_sign "Angular velocity sign: 0=positive, 1=negative";
CM_ SG_ 194 LW1_ID "Calibration ID - 0=not calibrated, 128=calibrated (PQ35/46/VW32x/VW411)";
CM_ SG_ 194 LW1_init_source "Initialization source";
CM_ SG_ 194 LW1_status "Sensor status";
CM_ SG_ 194 LW1_status_KL30 "Terminal 30 status (Kostal sensor)";
CM_ SG_ 194 LW1_counter "Free running message counter";
CM_ SG_ 194 LW1_coding "Coding data (multiplex output depends on counter)";
CM_ SG_ 194 LW1_CRC "Checksum - One's complement of 8-bit sum of bytes 1,2,3,4,6";

CM_ SG_ 210 LM_Offset "centiNewton-meters for ease of calculation without FP math in Panda";
CM_ SG_ 210 Vib_Amp "Steering wheel haptic, amplitude";
CM_ SG_ 210 Vib_Freq "Steering wheel haptic, frequency";

CM_ SG_ 416 BR1_ASR_request "ASR request to engine - requests in bytes 5 and 6 to be executed";
CM_ SG_ 416 BR1_MSR_request "MSR request - when set, byte 6 contains inverse MSR torque";
CM_ SG_ 416 BR1_ABS_brake "ABS control active (including pressure reduction)";
CM_ SG_ 416 BR1_EDS_Ongr "Electronic differential lock intervention";
CM_ SG_ 416 BR1_ESP_Ongr "ESP driving dynamics control intervention";
CM_ SG_ 416 BR1_ASR_Ongr "ASR transmission switching influence";
CM_ SG_ 416 BR1_EBV_Ongr "Electronic brake force distribution intervention";
CM_ SG_ 416 BR1_lamp_ABS "ABS safety warning lamp";
CM_ SG_ 416 BR1_lamp_ASR "ASR/ESP lamp (including flashing info)";
CM_ SG_ 416 BR1_lamp_BK "Brake control lamp (red)";
CM_ SG_ 416 BR1_light_switch "Brake light switch / brake pressure threshold exceeded";
CM_ SG_ 416 BR1_status_pressure_threshold "Brake test switch / pressure threshold status";
CM_ SG_ 416 BR1_MAD "OBD rough road suppression";
CM_ SG_ 416 BR1_status_MAD "Rough road suppression status";
CM_ SG_ 416 BR1_diagnosis "ABS diagnosis mode active";
CM_ SG_ 416 BR1_BKV_active "Active brake booster installed and not faulty";
CM_ SG_ 416 BR1_wheel_kmh "Vehicle speed (mean of driven wheels or ABS reference)";
CM_ SG_ 416 BR1_ASRMo_sl "ASR engagement torque slow (0-99.06%)";
CM_ SG_ 416 BR1_ASRMo_fa "ASR engagement torque fast when MSR_request=0 (0-99.06%)";
CM_ SG_ 416 BR1_MSR_Mo_inv "Inverse MSR torque when MSR_request=1 (99.06-0%)";
CM_ SG_ 416 BR1_MSR_Mo "MSR engagement torque (0-99.06%)";
CM_ SG_ 416 BR1_counter "Message counter to mark intervention moment";
CM_ SG_ 416 BR1_ASR_ESP "Control unit type: 0=ABS/EDS, 1=ASR/ESP/MABS";
CM_ SG_ 416 BR1_ESPASR_passive "ESP/ASR passive or deactivated by driver";
CM_ SG_ 416 BR1_status_ESP "ESP error status (fault memory entry)";
CM_ SG_ 416 BR1_replacement_Kmh "Speed is substitute value (sensor defect)";

CM_ SG_ 640 inner_engine_torque "Engine Indicated Torque";
CM_ SG_ 640 driver_desired_torque "Driver Requested Torque";
CM_ SG_ 640 mechanical_engine_loss_torque "Mechanical Torque Loss";
CM_ SG_ 640 accelerator_pedal_value_or_throttle "Accelerator Pedal or Throttle Position";
CM_ SG_ 640 engine_rpm "Engine Speed";
CM_ SG_ 640 torque_values_inaccurate "Approximate Torque Values";
CM_ SG_ 640 inner_engine_torque_without_external "Inner torque without external";

CM_ SG_ 644 MOB_CHECKSUM "Checksum MOB";
CM_ SG_ 644 MOB_COUNTER "Counter MOB";

CM_ BO_ 648 "engine message 2 - Contains engine status, temperatures, and torque information";
CM_ SG_ 648 MO2_Mp_code "Multiplex code - switches after 4 transmissions";
CM_ SG_ 648 MO2_transmission_code "Transmission code (multiplex value when Mp_Code=2)";
CM_ SG_ 648 MO2_max_torque "Maximum torque MDI (multiplex value when Mp_Code=3)";
CM_ SG_ 648 MO2_CAN_version "CAN version (multiplex value when Mp_Code=0)";
CM_ SG_ 648 MO2_motor_code "engine code (multiplex value when Mp_Code=1)";
CM_ SG_ 648 MO2_coolant_T "Engine coolant temperature or substitute value";
CM_ SG_ 648 MO2_BLS "Brake light switch - unfiltered raw signal";
CM_ SG_ 648 MO2_BTS "Brake test switch";
CM_ SG_ 648 MO2_Sta_coolant "Coolant temperature status - 0=OK, 1=Not OK";
CM_ SG_ 648 MO2_Sta_climate "Air conditioning compressor status";
CM_ SG_ 648 MO2_Sta_No_operation "Normal operation status (Terminal 15 on, init complete)";
CM_ SG_ 648 MO2_Status_TSK "Drive train coordinator status";
CM_ SG_ 648 MO2_Sta_GRA "GRA/ACC status";
CM_ SG_ 648 TSK_limiter_selected "Speed limiter selected";
CM_ SG_ 648 MO2_GRA_controls "GRA regulating to displayed speed";
CM_ SG_ 648 MO2_Sport_Error "Sport mode error (Porsche Cayenne)";
CM_ SG_ 648 MO2_OffRoad "OffRoad mode active";
CM_ SG_ 648 MO2_RME_content "Rapeseed oil methyl ester content (diesel)";
CM_ SG_ 648 MO2_GRA_target "GRA target speed setpoint";
CM_ SG_ 648 MO2_LL_target_speed "Idle target speed";
CM_ SG_ 648 MO2_limit_Mo "Limiting torque - max possible at speed";
CM_ SG_ 648 MO2_Mo_ZWR "Minimum engine torque with ignition angle retardation";

CM_ SG_ 896 MO3_preglow "Pre-glow active (diesel engines)";
CM_ SG_ 896 MO3_Prio_Dz "Engine speed priority: 0=request, 1=mandatory";
CM_ SG_ 896 MO_switch_StartStopp "Start/stop deactivated by driver (LED on when 0)";
CM_ SG_ 896 MO3_winter_program "Winter driving program active";
CM_ SG_ 896 MO3_Sta_pedal "Accelerator pedal status: 0=OK, 1=substitute value";
CM_ SG_ 896 MO3_Sta_FPG "Accelerator pedal gradient control bit (multiplexer for byte 8)";
CM_ SG_ 896 MO3_Sign_FPG "Accelerator pedal gradient sign (only when MO3_Sta_FPG=1)";
CM_ SG_ 896 MO3_Sta_temp "Intake air temperature status: 0=OK, 1=substitute value";
CM_ SG_ 896 MO3_offset_temp "Intake air temperature";
CM_ SG_ 896 MO3_pedal_value "Accelerator pedal raw signal (0-101.6%)";
CM_ SG_ 896 MO3_wheel_Wu_torque "Wheel torque request (12-bit value, 0-1596.66% MDI)";
CM_ SG_ 896 MO3_sign_wheelWu "Wheel torque sign: 0=positive, 1=negative";
CM_ SG_ 896 MO3_release_coasting "Sailing operation enable for transmission";
CM_ SG_ 896 MO_StartStopp_stop_preparation "Engine stop in preparation";
CM_ SG_ 896 MO3_Dz_influence "Engine speed influence factor (0-100% interpolation)";
CM_ SG_ 896 MO3_target_Dz "Desired engine speed (when MO3_Prio_Dz=1)";
CM_ SG_ 896 MO3_DKW "Throttle valve position when MO3_Sta_FPG=0 (0-101.6%)";
CM_ SG_ 896 MO3_FPGradient "Accelerator pedal gradient when MO3_Sta_FPG=1 (0-6350%/s)";

CM_ SG_ 912 GK1_driver_door_contact "Status of the driver's door rotary latch";
CM_ SG_ 912 BSK_HL_opened "Status of the rear left door rotary latch";
CM_ SG_ 912 BSK_HR_opened "Status of the rear right door rotary latch";
CM_ SG_ 912 BSK_BT_opened "Status of the passenger door rotary latch";
CM_ SG_ 912 BSK_HD_main_detent "Status of trunk lid main detent";

CM_ BO_ 1088 "Transmission 1 - Contains gear status, torque requests, and control signals";

CM_ SG_ 1088 GE1_shifting "Gear shift active: 0=no shift, 1=shift in progress";
CM_ SG_ 1088 GE1_status_protection "Transmission/converter protection request (power reduction or ignition angle)";
CM_ SG_ 1088 GE1_AC_compressor "AC compressor off request";
CM_ SG_ 1088 GE1_WK "Torque converter clutch status";
CM_ SG_ 1088 GE1_StSt_info "Start/stop coordinator info";
CM_ SG_ 1088 GE1_EGS_request "EGS request - byte 4 becomes valid when set";
CM_ SG_ 1088 GE1_target_gear "Target gear when shifting or current gear";
CM_ SG_ 1088 GE1_selection_Pos "Selector lever position / driving program";
CM_ SG_ 1088 GE1_Mrad_Mkurb "Wheel torque to crankshaft torque ratio (Mrad/Mcrank)";
CM_ SG_ 1088 GE1_target_Mo "Internal target engine torque request (0-99.06%)";
CM_ SG_ 1088 GE1_Fahrwistd "Driving resistance index (normalized % slope)";
CM_ SG_ 1088 GE1_limp_home "Emergency mode status";
CM_ SG_ 1088 GE1_cooling "Cooling request level";
CM_ SG_ 1088 GE1_status_OBD "OBD status - MIL lamp control";
CM_ SG_ 1088 GE1_LaunchControl "Launch control active";
CM_ SG_ 1088 GE1_info_bit "Transmission type: 0=stepped automatic, 1=CVT";
CM_ SG_ 1088 GE1_SleepInd "Sleep readiness after terminal 15 off";
CM_ SG_ 1088 GE1_counter "Message counter (synchronized with transmission_2)";
CM_ SG_ 1088 GE1_fault_entry "Fault memory entry present";
CM_ SG_ 1088 GE1_WaVerl_Mo "Transmission torque loss / clutch torque (0-99.06%)";

CM_ SG_ 1056 fault_status_outside_temp_4_1 "ambient temp error";
CM_ SG_ 1056 fault_status_oil_temperature_4_1 "oil temp error";
CM_ SG_ 1056 fault_status_coolant_temp_4_1 "water temp error";
CM_ SG_ 1056 outside_temperature_filtered "outside temp, filtered";
CM_ SG_ 1056 oil_temperature_4_1 "kombi oil temperature";
CM_ SG_ 1056 coolant_temp_4_1_Kombi_2 "kombi coolant temperature";

CM_ SG_ 1096 counter_selector_lever_1 "Counter selector_lever_1";

CM_ BO_ 1152 "engine message 5 - Contains engine type, consumption, lamps, and diagnostic info";

CM_ SG_ 1152 MO5_Mp_Code "Multiplex selector - switches every 4 transmissions";
CM_ SG_ 1152 MO5_max_torque "Maximum torque when Mp_Code=0 (0-630 Nm)";
CM_ SG_ 1152 MO5_engine_speed "Engine speed at max torque when Mp_Code=1 (0-6300 RPM)";
CM_ SG_ 1152 MO5_engine_type "Engine type info when Mp_Code=2 (cylinder count, turbo, fuel type)";
CM_ SG_ 1152 MO5_exhaust_type "Exhaust type EOBD when Mp_Code=3";
CM_ SG_ 1152 MO5_exhaust_type2 "Exhaust type OBD when Mp_Code=3";
CM_ SG_ 1152 MO5_exhaust_type3 "DPF installed when Mp_Code=3";
CM_ SG_ 1152 OBD_cold_start_Denominator "Cold start denominator increment when Mp_Code=3";
CM_ SG_ 1152 OBD_Minimum_Trip "Minimum normalized trip when Mp_Code=3";
CM_ SG_ 1152 MO5_DPF_reg "DPF regenerating when Mp_Code=3";
CM_ SG_ 1152 MO5_preheat "Diesel pre-glow lamp";
CM_ SG_ 1152 MO5_E_throttle "E-Gas system lamp (petrol only)";
CM_ SG_ 1152 MO5_OBD_2 "OBD/MIL lamp control";
CM_ SG_ 1152 MO5_hot_run "Coolant overheat warning lamp";
CM_ SG_ 1152 MO5_climate_compressor "AC compressor off request";
CM_ SG_ 1152 MO5_field_cooling "Map cooling installed and OK";
CM_ SG_ 1152 MO5_KliKo_Red "AC compressor power reduction";
CM_ SG_ 1152 MO5_consumption "Fuel consumption counter (15-bit, µl)";
CM_ SG_ 1152 MO5_overflow_consumption "Consumption counter overflow";
CM_ SG_ 1152 MO5_fan "Cooling fan PWM control (0-101.6%)";
CM_ SG_ 1152 MO5_HLeuchte "Overheat pre-warning";
CM_ SG_ 1152 MO5_particle_lamp "Particle filter lamp";
CM_ SG_ 1152 MO5_Sta_BKU "Brake vacuum pump status (Porsche only)";
CM_ SG_ 1152 MO5_type_start_control "Starter control type: 0=BSG/BCM, 1=MSG";
CM_ SG_ 1152 MO5_TDE_lamp "Fuel cap warning lamp (petrol only)";
CM_ SG_ 1152 MO5_TDE_Text "Fuel cap text display (petrol only)";
CM_ SG_ 1152 MO5_DZM_damping "RPM gauge damping control";
CM_ SG_ 1152 MO5_Interlock "Interlock switch for manual transmission start";
CM_ SG_ 1152 MO5_Start "Automatic start permission";
CM_ SG_ 1152 MO5_starter "Starter control permission";
CM_ SG_ 1152 MO5_GRA_main_switch "GRA main switch / readiness";
CM_ SG_ 1152 MO5_torques "MDI torque values doubled";
CM_ SG_ 1152 MO5_engine_text1 "Text: Engine workshop";
CM_ SG_ 1152 MO5_engine_text2 "Text: Exhaust workshop (deprecated)";
CM_ SG_ 1152 MO5_engine_text3 "Text: Fuel system fault";
CM_ SG_ 1152 MO5_engine_text4 "Text: Particle filter needs regeneration";
CM_ SG_ 1152 CHECKSUM "Checksum with final value 0x0";

CM_ SG_ 1160 counter_engine_6 "Counter engine_6";
CM_ SG_ 1160 altitude_info_engine_6 "Altitude Correction";
CM_ SG_ 1160 actual_torque_for_transmission "Actual torque for gear";
CM_ SG_ 1160 desired_torque_for_transmission "Target torque for gearbox";
CM_ SG_ 1160 checksum_engine_6 "Checksum engine_6";
CM_ SG_ 1160 GRA_desired_acceleration "GRA target acceleration";
CM_ SG_ 1160 feedback_torque "Feedback torque-integral gear intervention";

CM_ SG_ 1344 counter_transmission_2 "Counter transmission_2";
CM_ SG_ 1344 upshift_lamp "Upshift Flag";

CM_ SG_ 1386 ACA_V_desired "255=unset";

CM_ SG_ 1408 counter_engine_Flexia "Counter engine_Flexia";
CM_ SG_ 1408 combustion_type "Type of combustion";
CM_ SG_ 1408 Max_torque "Maximum torque";
CM_ SG_ 1408 rpm_MaxNorm "RPM of maximum torque";
CM_ SG_ 1408 displacement "Displacement";
CM_ SG_ 1408 number_of_cylinders "Number of cylinders";
CM_ SG_ 1408 number_of_valves "Number of valves";
CM_ SG_ 1408 intake_system "Induction System";
CM_ SG_ 1408 engine_power "Maximum engine power";

CM_ SG_ 1416 boost_pressure "Boost Pressure";
CM_ SG_ 1416 engine_rpm_gradient "Engine speed gradient";
CM_ SG_ 1416 altitude_info_engine_7 "Altitude correction factor";
CM_ SG_ 1416 oil_temperature "Oil temperature";

CM_ SG_ 1470 LDW_Direction "0=right,1=left";
CM_ SG_ 1470 XX_DLCORTLC1 "Might be DLC or TLC";
CM_ SG_ 1470 XX_DLCORTLC2 "Might be DLC or TLC, might have wrong size";

CM_ SG_ 1550 MFA_v_Signal_02 "0=km/h, 1=mph";

SG_MUL_VAL_ 416 BR1_ASRMo_fa BR1_MSR_request 0-0;
SG_MUL_VAL_ 416 BR1_MSR_Mo_inv BR1_MSR_request 1-1;

SG_MUL_VAL_ 896 MO3_DKW MO3_Sta_FPG 0-0;
SG_MUL_VAL_ 896 MO3_FPGradient MO3_Sta_FPG 1-1;
SG_MUL_VAL_ 896 MO3_Sign_FPG MO3_Sta_FPG 1-1;

VAL_ 194 LW1_LRW_sign 0 "positive_sign" 1 "negative_sign";
VAL_ 194 LW1_speed_sign 0 "positive_sign" 1 "negative_sign";
VAL_ 194 LW1_ID 0 "not_yet_calibrated" 128 "calibrated_only_for_PQ35_46_VW32x_VW411";
VAL_ 194 LW1_init_source 0 "brake_3" 1 "eps_bit";
VAL_ 194 LW1_status 0 "OK" 1 "no_initial" 2 "sporadic_failure" 3 "permanent_failure";
VAL_ 194 LW1_status_KL30 0 "ok" 1 "no_init_s";

VAL_ 416 BR1_ASR_request 0 "no_requirement" 1 "ASR_requirement";
VAL_ 416 BR1_MSR_request 0 "no_requirement" 1 "MSR_requirement";
VAL_ 416 BR1_ABS_brake 0 "no_ABS_control" 1 "ABS_control";
VAL_ 416 BR1_EDS_Ongr 0 "no_EDS_intervention" 1 "EDS_intervention";
VAL_ 416 BR1_ESP_Ongr 0 "no_ESP_intervention" 1 "ESP_intervention";
VAL_ 416 BR1_ASR_Ongr 0 "no_requirement" 1 "ASR_shift_map" 2 "downshift" 3 "switching_ban";
VAL_ 416 BR1_EBV_Ongr 0 "no_EBV_intervention" 1 "EBV_intervention";
VAL_ 416 BR1_lamp_ABS 0 "lamp_off" 1 "lamp_on";
VAL_ 416 BR1_lamp_ASR 0 "lamp_off" 1 "lamp_on";
VAL_ 416 BR1_lamp_BK 0 "lamp_off" 1 "lamp_on";
VAL_ 416 BR1_light_switch 0 "no_braking_threshold_not_reached" 1 "brake_applied_threshold_exceeded";
VAL_ 416 BR1_status_pressure_threshold 0 "state_valid_bkv_not_requested_no_brake" 1 "state_not_available_bkv_requested_brake";
VAL_ 416 BR1_MAD 0 "no_fade_out" 1 "fade_out";
VAL_ 416 BR1_status_MAD 0 "valid" 1 "invalid";
VAL_ 416 BR1_diagnosis 0 "no" 1 "in_diagnosis";
VAL_ 416 BR1_BKV_active 0 "BKV_not_installed_or_fault" 1 "BKV_installed_and_not_fault";
VAL_ 416 BR1_ASR_ESP 0 "ABS_ABS_EDS" 1 "ASR_ESP_MABS";
VAL_ 416 BR1_ESPASR_passive 0 "ESP_ASR_activated" 1 "esp_or_asr_passive_held_or_function_switch_or_roller_mode";
VAL_ 416 BR1_status_ESP 0 "ok" 1 "Failure";
VAL_ 416 BR1_replacement_Kmh 0 "OK" 1 "substitute_value";

SG_MUL_VAL_ 648 MO2_transmission_code MO2_Mp_code 2-2;
SG_MUL_VAL_ 648 MO2_max_torque MO2_Mp_code 3-3;
SG_MUL_VAL_ 648 MO2_CAN_version MO2_Mp_code 0-0;
SG_MUL_VAL_ 648 MO2_motor_code MO2_Mp_code 1-1;

SG_MUL_VAL_ 1152 MO5_max_torque MO5_Mp_Code 0-0;
SG_MUL_VAL_ 1152 MO5_engine_speed MO5_Mp_Code 1-1;
SG_MUL_VAL_ 1152 MO5_engine_type MO5_Mp_Code 2-2;
SG_MUL_VAL_ 1152 MO5_exhaust_type MO5_Mp_Code 3-3;
SG_MUL_VAL_ 1152 MO5_exhaust_type2 MO5_Mp_Code 3-3;
SG_MUL_VAL_ 1152 MO5_exhaust_type3 MO5_Mp_Code 3-3;
SG_MUL_VAL_ 1152 OBD_cold_start_Denominator MO5_Mp_Code 3-3;
SG_MUL_VAL_ 1152 OBD_Minimum_Trip MO5_Mp_Code 3-3;
SG_MUL_VAL_ 1152 MO5_DPF_reg MO5_Mp_Code 3-3;

VAL_ 648 MO2_Mp_code 0 "can_standstill" 1 "engine_coding" 2 "transmission_coding" 3 "MDI_Max";

VAL_ 648 MO2_transmission_code 0 "_5HP19" 1 "_5HP24" 2 "AG4" 3 "vl300" 4 "VQ250" 5 "VQ35" 6 "AG4_yestco" 7 "AG5_yestco" 8 "auto_clutch" 9 "auto_clutch_with_ASG" 10 "AG6_yestco_ZF_6HP_AISIN" 11 "DQ500_DQ250_DQ200" 12 "sq100_sq200" 14 "AL1000_AL551_AL951_ZF8HPx" 15 "manual_shifter_conventional" 16 "DL800" 17 "e_vehicle_single_gear";

VAL_ 648 MO2_BLS 0 "no_braking" 1 "brake_applied";
VAL_ 648 MO2_BTS 0 "no_braking" 1 "Brake_activated";
VAL_ 648 MO2_Sta_coolant 0 "temperature_ok" 1 "temperature_not_ok";
VAL_ 648 MO2_Sta_climate 0 "climate_off" 1 "climate_on";
VAL_ 648 MO2_Sta_No_operation 0 "no_normal_operation" 1 "normal_operation";
VAL_ 648 MO2_Status_TSK 0 "tsk_not_available" 1 "tsk_available";
VAL_ 648 MO2_Sta_GRA 0 "ADR_GRA_off" 1 "gra_activated_lamp_on" 2 "gra_overdriven_lamp_on" 3 "ADR_gra_faulted";
VAL_ 648 TSK_limiter_selected 0 "no_limiter_selected" 1 "Limiter_Selected";
VAL_ 648 MO2_GRA_controls 0 "no" 1 "yes";
VAL_ 648 MO2_Sport_Error 0 "no_failure" 1 "Failure";
VAL_ 648 MO2_OffRoad 0 "not_active" 1 "active";

VAL_ 870 AWV_text 0 "no_text" 1 "front_assist_off" 2 "front_assist_starting" 3 "front_assist_warning" 4 "front_assist_sensor_cleaning" 5 "front_assist_failure" 6 "front_assist_demo" 7 "lead" 8 "braking_currently_being_performed" 9 "sensor_not_available" 10 "clean_sensor" 11 "service_required_failure" 12 "function_by_driver_deactivated" 13 "function_by_driver_activated" 14 "front_assist_currently_not_available_rev_failure";
VAL_ 870 AWV_1_enable 0 "not_released" 1 "released";
VAL_ 870 AWV_1_Prefill 0 "no_prefill_request" 1 "prefill_request";
VAL_ 870 AWV_1_parameter 0 "default_parameter_set" 1 "par_slightly_increased_reception" 2 "par_increased_reception" 3 "par_highest_reception";
VAL_ 870 AWV_only 0 "acc_and_awv_installed" 1 "awv_without_acc_installed";
VAL_ 870 AWV_CityANB_variant 0 "auto_braking_in_entire_speed_range" 1 "auto_braking_in_defined_speed_range";
VAL_ 870 AWV_hold 0 "no_request" 1 "request_to_hold_vehicle_at_standstill";
VAL_ 870 ANB_partial_braking_enable 0 "partial_braking_not_enabled" 1 "partial_braking_enabled";
VAL_ 870 AWV_2_status 0 "lamp_off" 1 "lamp_on";
VAL_ 870 AWV_2_fault 0 "lamp_off" 1 "lamp_on";
VAL_ 870 AWV_2_SU_warning_time 0 "early" 1 "normal" 2 "late" 3 "adaptive";
VAL_ 870 AWV_2_SU_brake_jerk 0 "brake_jerk_deactivated" 1 "brake_jerk_activated";
VAL_ 870 AWV_2_SU_gong 0 "chime_deactivated" 1 "chime_activated";
VAL_ 870 AWV_2_SU_lamp 0 "lamp_deactivated" 1 "lamp_activated";
VAL_ 870 AWV_2_surroundings_warning 0 "no_warning" 1 "warning";
VAL_ 870 AWV_2_enable 0 "no_jerk_release" 1 "jerk_release";
VAL_ 870 AWV_2_jerk_profile 0 "no_jerk" 1 "jerk_profile_1" 2 "jerk_profile_2" 3 "jerk_profile_3" 4 "jerk_profile_4" 5 "jerk_profile_5" 6 "not_allowed" 7 "not_allowed";
VAL_ 870 AWV_2_warning_tone 0 "off" 1 "on";
VAL_ 870 AWV_2_warning_symbol 0 "off" 1 "on";
VAL_ 870 AWV_info_tone 0 "off" 1 "on";
VAL_ 870 AWV_2_belt_tensioner 0 "belt_not_tension" 1 "belt_tension";
VAL_ 870 AWV_configuration_menu_request 0 "menu_deactivate" 1 "menu_activate";
VAL_ 870 AWV_configuration_forward_menu_request 0 "menu_deactivate" 1 "menu_activate";
VAL_ 870 AWV_configuration_status 0 "awv_inactive" 1 "awv_active";
VAL_ 870 AWV_configuration_forward_status 0 "awv_pre_warning_inactive" 1 "awv_pre_warning_active";
VAL_ 870 AWV_2_distance_warning 0 "no_warning_notice" 1 "warning_notice";
VAL_ 870 ANB_target_braking_enable 0 "target_braking_not_enabled" 1 "target_braking_enabled";
VAL_ 870 ANB_CM_request 0 "no_request" 1 "request_active";

VAL_ 872 ACS_status_ADR 2 "adr_passive" 0 "adr_not_active" 1 "adr_active" 3 "irrev_fault" ;
VAL_ 872 ACS_ADR_overrun 1 "deceleration_limited_to_coasting" 0 "deceleration_not_limited_to_coasting" ;
VAL_ 872 ACS_overrun_cutoff 1 "sa_not_permitted" 0 "sa_permitted" ;
VAL_ 872 ACS_start_stop_info 3 "system_fault" 0 "engine_running_nn" 1 "stop_ban_engine_start_nn" 2 "engine_startup_necessary" ;
VAL_ 872 ACS_torque_intervention 1 "moment_intervention_prevent" 0 "no_influence_torque_intervention_engine" ;
VAL_ 872 ACS_type_ACC 0 "basis_acc" 1 "acc_with_follow_to_stop" 3 "free" 2 "free" ;
VAL_ 872 ACS_enable_desired_accel 0 "target_accel_not_enabled" 1 "target_accel_enabled" ;
VAL_ 872 ACS_desired_accel 2046 "adr_not_active" 2047 "fault" ;
VAL_ 872 ACS_stop_desired 0 "no_hold_request" 1 "vehicle_stopping" ;
VAL_ 872 ACS_fault 1 "fault_memory_entry" 0 "no_fault_memory_entry" ;
VAL_ 872 ACS_permissible_control_deviation 254 "adr_not_active" 255 "fault" ;
VAL_ 872 ACS_max_change_gradient 254 "neutral_value" 0 "neutral_value" 255 "fault" ;

VAL_ 896 MO3_preglow 0 "no_preheating" 1 "preheating_active";
VAL_ 896 MO3_Prio_Dz 0 "desired" 1 "forced";
VAL_ 896 MO_switch_StartStopp 0 "start_stop_via_main_switch_deactivated_led_on" 1 "start_stop_via_main_switch_activated_led_off";
VAL_ 896 MO3_winter_program 0 "not_active" 1 "active";
VAL_ 896 MO3_Sta_pedal 0 "accelerator_pedal_ok" 1 "substitute_value";
VAL_ 896 MO3_Sta_FPG 0 "gradient_not_conditioned" 1 "gradient_conditioned";
VAL_ 896 MO3_Sign_FPG 0 "positive_sign" 1 "negative_sign";
VAL_ 896 MO3_Sta_temp 0 "sensor_ok" 1 "substitute_value";
VAL_ 896 MO3_sign_wheelWu 0 "positive_sign" 1 "negative_sign";
VAL_ 896 MO3_release_coasting 0 "coasting_mode_not_enabled" 1 "coasting_mode_enabled";
VAL_ 896 MO_StartStopp_stop_preparation 0 "engine_stop_not_in_preparation" 1 "engine_stop_in_preparation";
CM_ BO_ 896 "engine message 3 - Contains accelerator pedal, temperatures, and control signals";

VAL_ 978 LH2_Sta_HCA 0 "disabled" 1 "initializing" 2 "fault" 3 "ready" 4 "rejected" 5 "active" 7 "active";

VAL_ 1088 GE1_shifting 0 "no_circuit" 1 "circuit_is_running";
VAL_ 1088 GE1_status_protection 0 "no_protection" 1 "protection_requested";
VAL_ 1088 GE1_AC_compressor 0 "no_request" 1 "compressor_off";
VAL_ 1088 GE1_WK 0 "WK_open" 1 "WK_regulated" 2 "WK_closed" 3 "Failure";
VAL_ 1088 GE1_StSt_info 0 "engine_running_not_necessary_stop_release" 1 "engine_start_not_mandatory_necessary_stop_prohibition" 2 "engine_start_absolute_necessary_start_request" 3 "system_error";
VAL_ 1088 GE1_EGS_request 0 "no_requirement" 1 "EGS_requirement";
VAL_ 1088 GE1_target_gear 0 "P (Park) | Disengaged" 1 "Gear 1 | Engaged" 2 "Gear 2 | Engaged" 3 "Gear 3 | Engaged" 4 "Gear 4 | Engaged" 5 "Gear 5 | Engaged" 6 "1m Gear" 7 "gear_r" 8 "Gear 6 | Engaged" 9 "Gear 7 | Engaged" 10 "Gear 8 | Engaged" 14 "Speed Not Defined" 15 "Failure";
VAL_ 1088 GE1_selection_Pos 8 "P" 7 "R" 6 "N" 5 "D" 9 "U" 12 "S" 14 "T" 10 "T" 11 "T";
VAL_ 1088 GE1_limp_home 0 "No Emergency" 1 "No Switching" 2 "Switch to Neutral" 3 "50% Shifting Capacity" 4 "Driving Without UK" 5 "No Emeregency" 6 "No Emergency" 7 "No Emergency, Target Shifting Reached" 15 "Failure";
VAL_ 1088 GE1_cooling 0 "No Additional Cooling Requested" 1 "20% Additional Fan Cooling Requested" 2 "40% Additional Fan Cooling Requested" 3 "Maximum Additional Fan Cooling Requested";
VAL_ 1088 GE1_status_OBD 0 "MIL Off" 1 "MIL On";
VAL_ 1088 GE1_LaunchControl 0 "Launch Control Not Active" 1 "Launch Control Program Active";
VAL_ 1088 GE1_info_bit 0 "Standard Automatic" 1 "CVT";
VAL_ 1088 GE1_SleepInd 0 "CAN is Required" 1 "Sleep Ready";
VAL_ 1088 GE1_fault_entry 0 "No Failure Memory Entry" 1 "Failure Memory Entry";

VAL_ 1152 MO5_Mp_Code 0 "max_moment" 1 "engine_speed" 2 "engine_type" 3 "exhaust_type_or_norm_consumption";
VAL_ 1152 MO5_exhaust_type 0 "no_EOBD" 1 "EOBD";
VAL_ 1152 MO5_exhaust_type2 0 "no_OBD" 1 "OBD";
VAL_ 1152 MO5_exhaust_type3 0 "no_DPF_installed" 1 "dpf_installed";
VAL_ 1152 OBD_cold_start_Denominator 0 "denominator_not_count_up" 1 "conditions_to_increment_cold_start_denom_met";
VAL_ 1152 OBD_Minimum_Trip 0 "no_min_normed_trip" 1 "Min_Normed_Trip";
VAL_ 1152 MO5_DPF_reg 0 "dpf_not_regenerating" 1 "dpf_regenerating";
VAL_ 1152 MO5_preheat 0 "lamp_off" 1 "lamp_on";
VAL_ 1152 MO5_E_throttle 0 "lamp_off" 1 "lamp_on";
VAL_ 1152 MO5_OBD_2 0 "lamp_off" 1 "lamp_on";
VAL_ 1152 MO5_hot_run 0 "lamp_off" 1 "lamp_on";
VAL_ 1152 MO5_climate_compressor 0 "no_request" 1 "ac_compressor_off";
VAL_ 1152 MO5_field_cooling 0 "no" 1 "yes";
VAL_ 1152 MO5_KliKo_Red 0 "no" 1 "yes";
VAL_ 1152 MO5_overflow_consumption 0 "no_overflow" 1 "overflowed_at_least_once";
VAL_ 1152 MO5_HLeuchte 0 "no_warning" 1 "pre_warning";
VAL_ 1152 MO5_particle_lamp 0 "lamp_off" 1 "lamp_on";
VAL_ 1152 MO5_Sta_BKU 0 "ok_or_not_installed" 1 "not_ok";
VAL_ 1152 MO5_type_start_control 0 "starter_control_bsg_bcm_kessyd1_zas" 1 "starter_control_by_msg";
VAL_ 1152 MO5_TDE_lamp 0 "lamp_off" 1 "lamp_on";
VAL_ 1152 MO5_TDE_Text 0 "no_text" 1 "text_display_per_iso";
VAL_ 1152 MO5_DZM_damping 0 "normal_damping" 1 "dynamic_damping";
VAL_ 1152 MO5_Interlock 0 "interlock_not_applied" 1 "interlock_applied";
VAL_ 1152 MO5_Start 0 "start_not_permitted" 1 "start_release";
VAL_ 1152 MO5_starter 0 "starter_may_be_actuated" 1 "starter_disengage_actuation_not_possible";
VAL_ 1152 MO5_GRA_main_switch 0 "off" 1 "on";
VAL_ 1152 MO5_torques 0 "single" 1 "double";
VAL_ 1152 MO5_engine_text1 0 "no_text" 1 "text_1";
VAL_ 1152 MO5_engine_text2 0 "no_text" 1 "text_2";
VAL_ 1152 MO5_engine_text3 0 "no_text" 1 "text_3";
VAL_ 1152 MO5_engine_text4 0 "no_text" 1 "text_4";

VAL_ 1386 ACA_status_ACC 6 "acc_rev_off" 0 "main_switch_off" 4 "acc_in_background" 3 "acc_active" 1 "reserve" 2 "acc_passive" 7 "acc_irrev_off" 5 "free" ;
VAL_ 1386 ACA_ID_status_ACC 0 "no_display" ;
VAL_ 1386 ACA_driver_hint 1 "on" 0 "off" ;
VAL_ 1386 ACA_display_count 1 "display_expected" 0 "display_not_expected" ;
VAL_ 1386 ACA_time_gap 3 "time_gap3" 10 "time_gap10" 4 "time_gap4" 14 "time_gap14" 11 "time_gap11" 2 "time_gap2" 13 "time_gap13" 9 "time_gap9" 1 "time_gap1" 8 "time_gap8" 5 "time_gap5" 15 "time_gap15" 0 "not_defined" 12 "time_gap12" 6 "time_gap6" 7 "time_gap7" ;
VAL_ 1386 ACA_V_desired 255 "no_value_in_memory" ;
VAL_ 1386 ACA_kmh_mph 0 "km_h" 1 "mph" ;
VAL_ 1386 ACA_acoustic1 0 "no_chime" 1 "chime" ;
VAL_ 1386 ACA_acoustic2 0 "no_buzzer" 1 "buzzer" ;
VAL_ 1386 ACA_prio_display 1 "medium_prio" 3 "no_display_request" 0 "high_prio" 2 "low_prio" ;
VAL_ 1386 ACA_measured_time_gap 6 "time_gap6" 2 "time_gap2" 7 "time_gap7" 13 "time_gap13" 11 "time_gap11" 4 "time_gap4" 8 "time_gap8" 12 "time_gap12" 10 "time_gap10" 0 "no_object_detected" 1 "time_gap1" 3 "time_gap3" 9 "time_gap9" 15 "time_gap15" 14 "time_gap14" 5 "time_gap5" ;
VAL_ 1386 ACA_ACC_deceleration 0 "acc_not_decelerating" 1 "acc_decelerating" ;
VAL_ 1386 ACA_status_GRA 3 "gra_active" 4 "gra_overridden" 2 "gra_passive" 0 "main_switch_off" 6 "free" 7 "gra_fault" 1 "reserve" 5 "free" ;
VAL_ 1386 ACA_ID_status_GRA 0 "no_display" ;
VAL_ 1386 ACA_coding 0 "ACC" 1 "GRA" ;
VAL_ 1386 ACA_speedo_ring 0 "not_illuminated" 1 "illuminated" ;
VAL_ 1386 ACA_change_time_gap 1 "display_requested" 0 "no_display" ;

VAL_ 1472 EP1_fault_status 0 "full_function" 1 "left_side_faulty" 2 "right_side_faulty" 3 "both_sides_faulty";
VAL_ 1472 EP1_status_EPB 0 "brake_open" 1 "brake_closed";
VAL_ 1472 EP1_status_switch 0 "full_function" 1 "switch_out_of_function";
VAL_ 1472 EP1_clamping_force 31 "fault";
VAL_ 1472 EP1_switch_info 0 "no_driver_request" 1 "driver_request_open" 2 "driver_request_close" 3 "switch_fault";
VAL_ 1472 EP1_status_NWS 0 "full_function" 1 "no_function";
VAL_ 1472 EP1_fault_entry 0 "no_fault_memory_entry" 1 "fault_memory_entry";
VAL_ 1472 EP1_release_Ver 0 "deceleration_request_not_enabled" 1 "deceleration_request_enabled";
VAL_ 1472 EP1_AutoHold_allowed 0 "pers_not_permitted" 1 "pers_permitted";
VAL_ 1472 EP1_AutoHold_active 0 "no" 1 "yes";
VAL_ 1472 EP1_SleepInd 0 "can_required" 1 "sleep_ready";
VAL_ 1472 EP1_status_Kl_15 0 "terminal_15_off" 1 "terminal_15_on";
VAL_ 1472 EP1_lamp_AutoP 0 "lamp_off" 1 "lamp_on";
VAL_ 1472 EP1_brake_light 0 "off" 1 "on";
VAL_ 1472 EP1_warning_tone1 0 "off" 1 "on";
VAL_ 1472 EP1_warning_tone2 0 "off" 1 "on";
VAL_ 1472 EP1_request_ShLock 0 "off" 1 "on";
VAL_ 1472 EPB_autohold_lamp 0 "lamp_off" 1 "lamp_on";
VAL_ 1472 EP1_QualNeigWi 0 "valid_value" 1 "substitute_init_or_fault_value";
VAL_ 1472 EP1_KuppModBer 0 "clutch_sensor_out_of_model_range" 1 "clutch_sensor_in_model_range" 2 "sensor_signal_inaccurate" 3 "sensor_defective";
VAL_ 1472 EP1_HydrHold 0 "vehicle_not_hydraulic_held" 1 "vehicle_hydraulic_held";
VAL_ 1472 EP1_function_lamp 0 "lamp_off" 1 "lamp_on";
VAL_ 1472 EP1_warning_tone 0 "warning_tone_off" 1 "warning_tone_on";
VAL_ 1472 EP1_fault_BKL 0 "bkl_off" 1 "bkl_on";
VAL_ 1472 EP1_fault_yellow 0 "lamp_off" 1 "lamp_on";
VAL_ 1472 EP1__text 0 "no_text" 1 "text_1" 2 "text_2" 3 "text_3" 4 "text_4" 5 "text_5" 6 "reserved" 7 "reserved" 8 "text_8";
